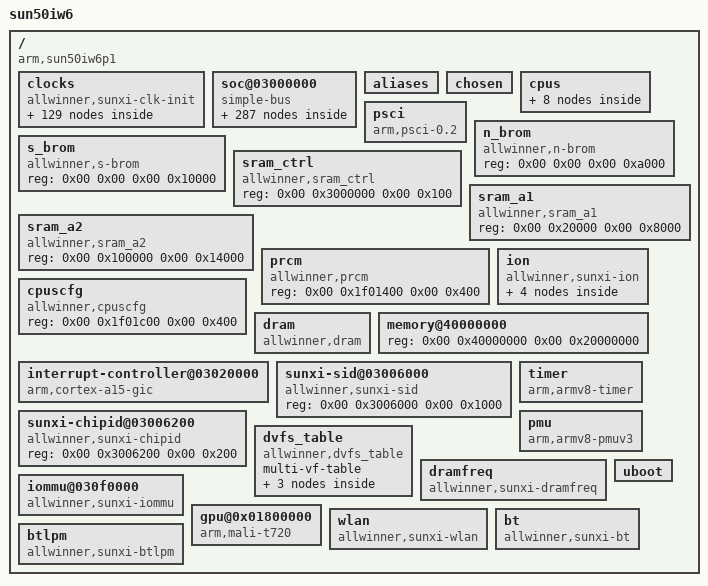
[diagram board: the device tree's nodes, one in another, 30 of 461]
/dts-v1/;

/memreserve/	0x0000000040020000 0x0000000000000800;
/memreserve/	0x0000000048000000 0x0000000001000000;
/memreserve/	0x0000000048100000 0x0000000000004000;
/memreserve/	0x0000000048104000 0x0000000000001000;
/memreserve/	0x0000000048105000 0x0000000000001000;
/ {
	model = "sun50iw6";
	compatible = "arm,sun50iw6p1";
	interrupt-parent = <0x01>;
	#address-cells = <0x02>;
	#size-cells = <0x02>;

	clocks {
		compatible = "allwinner,sunxi-clk-init";
		device_type = "clocks";
		#address-cells = <0x02>;
		#size-cells = <0x02>;
		ranges;
		reg = <0x00 0x3001000 0x00 0x1000 0x00 0x7010000 0x00 0x400 0x00 0x7000000 0x00 0x04>;

		losc {
			#clock-cells = <0x00>;
			compatible = "allwinner,fixed-clock";
			clock-frequency = <0x8000>;
			clock-output-names = "losc";
			linux,phandle = <0x0d>;
			phandle = <0x0d>;
		};

		iosc {
			#clock-cells = <0x00>;
			compatible = "allwinner,fixed-clock";
			clock-frequency = <0xf42400>;
			clock-output-names = "iosc";
			linux,phandle = <0x0e>;
			phandle = <0x0e>;
		};

		hosc {
			#clock-cells = <0x00>;
			compatible = "allwinner,fixed-clock";
			clock-frequency = <0x16e3600>;
			clock-output-names = "hosc";
			linux,phandle = <0x07>;
			phandle = <0x07>;
		};

		osc48m {
			#clock-cells = <0x00>;
			compatible = "allwinner,fixed-clock";
			clock-frequency = <0x2dc6c00>;
			clock-output-names = "osc48m";
			linux,phandle = <0x08>;
			phandle = <0x08>;
		};

		pll_cpu {
			#clock-cells = <0x00>;
			compatible = "allwinner,sunxi-pll-clock";
			lock-mode = "new";
			clock-output-names = "pll_cpu";
		};

		pll_ddr0 {
			#clock-cells = <0x00>;
			compatible = "allwinner,sunxi-pll-clock";
			lock-mode = "new";
			clock-output-names = "pll_ddr0";
			linux,phandle = <0xd7>;
			phandle = <0xd7>;
		};

		pll_periph0 {
			#clock-cells = <0x00>;
			compatible = "allwinner,sunxi-pll-clock";
			assigned-clock-rates = <0x23c34600>;
			lock-mode = "new";
			clock-output-names = "pll_periph0";
			linux,phandle = <0x02>;
			phandle = <0x02>;
		};

		pll_periph1 {
			#clock-cells = <0x00>;
			compatible = "allwinner,sunxi-pll-clock";
			assigned-clock-rates = <0x23c34600>;
			lock-mode = "new";
			clock-output-names = "pll_periph1";
			linux,phandle = <0x03>;
			phandle = <0x03>;
		};

		pll_gpu {
			#clock-cells = <0x00>;
			compatible = "allwinner,sunxi-pll-clock";
			lock-mode = "new";
			clock-output-names = "pll_gpu";
			linux,phandle = <0xd9>;
			phandle = <0xd9>;
		};

		pll_video0 {
			#clock-cells = <0x00>;
			compatible = "allwinner,sunxi-pll-clock";
			lock-mode = "new";
			clock-output-names = "pll_video0";
			linux,phandle = <0x05>;
			phandle = <0x05>;
		};

		pll_video1 {
			#clock-cells = <0x00>;
			compatible = "allwinner,sunxi-pll-clock";
			lock-mode = "new";
			assigned-clock-rates = <0x2367b880>;
			clock-output-names = "pll_video1";
			linux,phandle = <0x06>;
			phandle = <0x06>;
		};

		pll_ve {
			#clock-cells = <0x00>;
			compatible = "allwinner,sunxi-pll-clock";
			device_type = "clk_pll_ve";
			lock-mode = "new";
			clock-output-names = "pll_ve";
			linux,phandle = <0x17>;
			phandle = <0x17>;
		};

		pll_de {
			#clock-cells = <0x00>;
			compatible = "allwinner,sunxi-pll-clock";
			assigned-clock-rates = <0x297c1e00>;
			lock-mode = "new";
			clock-output-names = "pll_de";
			linux,phandle = <0x09>;
			phandle = <0x09>;
		};

		pll_hsic {
			#clock-cells = <0x00>;
			compatible = "allwinner,sunxi-pll-clock";
			lock-mode = "new";
			clock-output-names = "pll_hsic";
			linux,phandle = <0x3f>;
			phandle = <0x3f>;
		};

		pll_audio {
			#clock-cells = <0x00>;
			compatible = "allwinner,sunxi-pll-clock";
			lock-mode = "new";
			clock-output-names = "pll_audio";
			linux,phandle = <0x04>;
			phandle = <0x04>;
		};

		pll_periph0x2 {
			#clock-cells = <0x00>;
			compatible = "allwinner,fixed-factor-clock";
			clocks = <0x02>;
			clock-mult = <0x02>;
			clock-div = <0x01>;
			clock-output-names = "pll_periph0x2";
			linux,phandle = <0x1b>;
			phandle = <0x1b>;
		};

		pll_periph0x4 {
			#clock-cells = <0x00>;
			compatible = "allwinner,fixed-factor-clock";
			clocks = <0x02>;
			clock-mult = <0x04>;
			clock-div = <0x01>;
			clock-output-names = "pll_periph0x4";
		};

		periph32k {
			#clock-cells = <0x00>;
			compatible = "allwinner,fixed-factor-clock";
			clocks = <0x02>;
			clock-mult = <0x02>;
			clock-div = <0x8f0d>;
			clock-output-names = "periph32k";
		};

		pll_periph1x2 {
			#clock-cells = <0x00>;
			compatible = "allwinner,fixed-factor-clock";
			clocks = <0x03>;
			clock-mult = <0x02>;
			clock-div = <0x01>;
			clock-output-names = "pll_periph1x2";
			linux,phandle = <0x75>;
			phandle = <0x75>;
		};

		pll_audiox4 {
			#clock-cells = <0x00>;
			compatible = "allwinner,fixed-factor-clock";
			clocks = <0x04>;
			clock-mult = <0x04>;
			clock-div = <0x01>;
			clock-output-names = "pll_audiox4";
		};

		pll_audiox2 {
			#clock-cells = <0x00>;
			compatible = "allwinner,fixed-factor-clock";
			clocks = <0x04>;
			clock-mult = <0x02>;
			clock-div = <0x01>;
			clock-output-names = "pll_audiox2";
		};

		pll_video0x4 {
			#clock-cells = <0x00>;
			compatible = "allwinner,fixed-factor-clock";
			clocks = <0x05>;
			clock-mult = <0x04>;
			clock-div = <0x01>;
			clock-output-names = "pll_video0x4";
		};

		pll_video1x4 {
			#clock-cells = <0x00>;
			compatible = "allwinner,fixed-factor-clock";
			clocks = <0x06>;
			clock-mult = <0x04>;
			clock-div = <0x01>;
			clock-output-names = "pll_video1x4";
		};

		hoscd2 {
			#clock-cells = <0x00>;
			compatible = "allwinner,fixed-factor-clock";
			clocks = <0x07>;
			clock-mult = <0x01>;
			clock-div = <0x02>;
			clock-output-names = "hoscd2";
		};

		osc48md4 {
			#clock-cells = <0x00>;
			compatible = "allwinner,fixed-factor-clock";
			clocks = <0x08>;
			clock-mult = <0x01>;
			clock-div = <0x04>;
			clock-output-names = "osc48md4";
			linux,phandle = <0x39>;
			phandle = <0x39>;
		};

		pll_periph0d6 {
			#clock-cells = <0x00>;
			compatible = "allwinner,fixed-factor-clock";
			clocks = <0x02>;
			clock-mult = <0x01>;
			clock-div = <0x06>;
			clock-output-names = "pll_periph0d6";
		};

		cpu {
			#clock-cells = <0x00>;
			compatible = "allwinner,sunxi-periph-clock";
			clock-output-names = "cpu";
		};

		axi {
			#clock-cells = <0x00>;
			compatible = "allwinner,sunxi-periph-clock";
			clock-output-names = "axi";
		};

		cpuapb {
			#clock-cells = <0x00>;
			compatible = "allwinner,sunxi-periph-clock";
			clock-output-names = "cpuapb";
		};

		psi {
			#clock-cells = <0x00>;
			compatible = "allwinner,sunxi-periph-clock";
			clock-output-names = "psi";
		};

		ahb1 {
			#clock-cells = <0x00>;
			compatible = "allwinner,sunxi-periph-clock";
			clock-output-names = "ahb1";
		};

		ahb2 {
			#clock-cells = <0x00>;
			compatible = "allwinner,sunxi-periph-clock";
			clock-output-names = "ahb2";
		};

		ahb3 {
			#clock-cells = <0x00>;
			compatible = "allwinner,sunxi-periph-clock";
			clock-output-names = "ahb3";
		};

		apb1 {
			#clock-cells = <0x00>;
			compatible = "allwinner,sunxi-periph-clock";
			clock-output-names = "apb1";
		};

		apb2 {
			#clock-cells = <0x00>;
			compatible = "allwinner,sunxi-periph-clock";
			clock-output-names = "apb2";
			linux,phandle = <0xae>;
			phandle = <0xae>;
		};

		mbus {
			#clock-cells = <0x00>;
			compatible = "allwinner,sunxi-periph-clock";
			clock-output-names = "mbus";
		};

		de {
			#clock-cells = <0x00>;
			compatible = "allwinner,sunxi-periph-clock";
			assigned-clock-parents = <0x09>;
			assigned-clock-rates = <0x297c1e00>;
			clock-output-names = "de";
			linux,phandle = <0x87>;
			phandle = <0x87>;
		};

		di {
			#clock-cells = <0x00>;
			compatible = "allwinner,sunxi-periph-clock";
			clock-output-names = "di";
			linux,phandle = <0xac>;
			phandle = <0xac>;
		};

		gpu {
			#clock-cells = <0x00>;
			compatible = "allwinner,sunxi-periph-clock";
			clock-output-names = "gpu";
			linux,phandle = <0xda>;
			phandle = <0xda>;
		};

		ce {
			#clock-cells = <0x00>;
			compatible = "allwinner,sunxi-periph-clock";
			clock-output-names = "ce";
			linux,phandle = <0xab>;
			phandle = <0xab>;
		};

		ve {
			#clock-cells = <0x00>;
			compatible = "allwinner,sunxi-periph-clock";
			clock-output-names = "ve";
			linux,phandle = <0x18>;
			phandle = <0x18>;
		};

		emce {
			#clock-cells = <0x00>;
			compatible = "allwinner,sunxi-periph-clock";
			clock-output-names = "emce";
			linux,phandle = <0xaa>;
			phandle = <0xaa>;
		};

		vp9 {
			#clock-cells = <0x00>;
			compatible = "allwinner,sunxi-periph-clock";
			clock-output-names = "vp9";
			linux,phandle = <0x1a>;
			phandle = <0x1a>;
		};

		dma {
			#clock-cells = <0x00>;
			compatible = "allwinner,sunxi-periph-clock";
			clock-output-names = "dma";
			linux,phandle = <0x0c>;
			phandle = <0x0c>;
		};

		msgbox {
			#clock-cells = <0x00>;
			compatible = "allwinner,sunxi-periph-clock";
			clock-output-names = "msgbox";
			linux,phandle = <0x0f>;
			phandle = <0x0f>;
		};

		hwspinlock_rst {
			#clock-cells = <0x00>;
			compatible = "allwinner,sunxi-periph-clock";
			clock-output-names = "hwspinlock_rst";
			linux,phandle = <0x10>;
			phandle = <0x10>;
		};

		hwspinlock_bus {
			#clock-cells = <0x00>;
			compatible = "allwinner,sunxi-periph-clock";
			clock-output-names = "hwspinlock_bus";
			linux,phandle = <0x11>;
			phandle = <0x11>;
		};

		hstimer {
			#clock-cells = <0x00>;
			compatible = "allwinner,sunxi-periph-clock";
			clock-output-names = "hstimer";
		};

		avs {
			#clock-cells = <0x00>;
			compatible = "allwinner,sunxi-periph-clock";
			clock-output-names = "avs";
		};

		dbgsys {
			#clock-cells = <0x00>;
			compatible = "allwinner,sunxi-periph-clock";
			clock-output-names = "dbgsys";
		};

		pwm {
			#clock-cells = <0x00>;
			compatible = "allwinner,sunxi-periph-clock";
			clock-output-names = "pwm";
			linux,phandle = <0x93>;
			phandle = <0x93>;
		};

		iommu {
			#clock-cells = <0x00>;
			compatible = "allwinner,sunxi-periph-clock";
			clock-output-names = "iommu";
			linux,phandle = <0xd8>;
			phandle = <0xd8>;
		};

		sdram {
			#clock-cells = <0x00>;
			compatible = "allwinner,sunxi-periph-clock";
			clock-output-names = "sdram";
		};

		nand0 {
			#clock-cells = <0x00>;
			compatible = "allwinner,sunxi-periph-clock";
			clock-output-names = "nand0";
			linux,phandle = <0xb6>;
			phandle = <0xb6>;
		};

		nand1 {
			#clock-cells = <0x00>;
			compatible = "allwinner,sunxi-periph-clock";
			clock-output-names = "nand1";
			linux,phandle = <0xb7>;
			phandle = <0xb7>;
		};

		sdmmc0_mod {
			#clock-cells = <0x00>;
			compatible = "allwinner,sunxi-periph-clock";
			clock-output-names = "sdmmc0_mod";
			linux,phandle = <0x7b>;
			phandle = <0x7b>;
		};

		sdmmc0_bus {
			#clock-cells = <0x00>;
			compatible = "allwinner,sunxi-periph-clock";
			clock-output-names = "sdmmc0_bus";
			linux,phandle = <0x7c>;
			phandle = <0x7c>;
		};

		sdmmc0_rst {
			#clock-cells = <0x00>;
			compatible = "allwinner,sunxi-periph-clock";
			clock-output-names = "sdmmc0_rst";
			linux,phandle = <0x7d>;
			phandle = <0x7d>;
		};

		sdmmc1_mod {
			#clock-cells = <0x00>;
			compatible = "allwinner,sunxi-periph-clock";
			clock-output-names = "sdmmc1_mod";
			linux,phandle = <0x82>;
			phandle = <0x82>;
		};

		sdmmc1_bus {
			#clock-cells = <0x00>;
			compatible = "allwinner,sunxi-periph-clock";
			clock-output-names = "sdmmc1_bus";
			linux,phandle = <0x83>;
			phandle = <0x83>;
		};

		sdmmc1_rst {
			#clock-cells = <0x00>;
			compatible = "allwinner,sunxi-periph-clock";
			clock-output-names = "sdmmc1_rst";
			linux,phandle = <0x84>;
			phandle = <0x84>;
		};

		sdmmc2_mod {
			#clock-cells = <0x00>;
			compatible = "allwinner,sunxi-periph-clock";
			clock-output-names = "sdmmc2_mod";
			linux,phandle = <0x76>;
			phandle = <0x76>;
		};

		sdmmc2_bus {
			#clock-cells = <0x00>;
			compatible = "allwinner,sunxi-periph-clock";
			clock-output-names = "sdmmc2_bus";
			linux,phandle = <0x77>;
			phandle = <0x77>;
		};

		sdmmc2_rst {
			#clock-cells = <0x00>;
			compatible = "allwinner,sunxi-periph-clock";
			clock-output-names = "sdmmc2_rst";
			linux,phandle = <0x78>;
			phandle = <0x78>;
		};

		uart0 {
			#clock-cells = <0x00>;
			compatible = "allwinner,sunxi-periph-clock";
			clock-output-names = "uart0";
			linux,phandle = <0x1c>;
			phandle = <0x1c>;
		};

		uart1 {
			#clock-cells = <0x00>;
			compatible = "allwinner,sunxi-periph-clock";
			clock-output-names = "uart1";
			linux,phandle = <0x1f>;
			phandle = <0x1f>;
		};

		uart2 {
			#clock-cells = <0x00>;
			compatible = "allwinner,sunxi-periph-clock";
			clock-output-names = "uart2";
			linux,phandle = <0x22>;
			phandle = <0x22>;
		};

		uart3 {
			#clock-cells = <0x00>;
			compatible = "allwinner,sunxi-periph-clock";
			clock-output-names = "uart3";
			linux,phandle = <0x25>;
			phandle = <0x25>;
		};

		twi0 {
			#clock-cells = <0x00>;
			compatible = "allwinner,sunxi-periph-clock";
			clock-output-names = "twi0";
			linux,phandle = <0x28>;
			phandle = <0x28>;
		};

		twi1 {
			#clock-cells = <0x00>;
			compatible = "allwinner,sunxi-periph-clock";
			clock-output-names = "twi1";
			linux,phandle = <0x2b>;
			phandle = <0x2b>;
		};

		twi2 {
			#clock-cells = <0x00>;
			compatible = "allwinner,sunxi-periph-clock";
			clock-output-names = "twi2";
			linux,phandle = <0x2e>;
			phandle = <0x2e>;
		};

		twi3 {
			#clock-cells = <0x00>;
			compatible = "allwinner,sunxi-periph-clock";
			clock-output-names = "twi3";
			linux,phandle = <0x31>;
			phandle = <0x31>;
		};

		scr0 {
			#clock-cells = <0x00>;
			compatible = "allwinner,sunxi-periph-clock";
			clock-output-names = "scr0";
			linux,phandle = <0xad>;
			phandle = <0xad>;
		};

		scr1 {
			#clock-cells = <0x00>;
			compatible = "allwinner,sunxi-periph-clock";
			clock-output-names = "scr1";
			linux,phandle = <0xb2>;
			phandle = <0xb2>;
		};

		spi0 {
			#clock-cells = <0x00>;
			compatible = "allwinner,sunxi-periph-clock";
			clock-output-names = "spi0";
			linux,phandle = <0x67>;
			phandle = <0x67>;
		};

		spi1 {
			#clock-cells = <0x00>;
			compatible = "allwinner,sunxi-periph-clock";
			clock-output-names = "spi1";
			linux,phandle = <0x6b>;
			phandle = <0x6b>;
		};

		gmac {
			#clock-cells = <0x00>;
			compatible = "allwinner,sunxi-periph-clock";
			clock-output-names = "gmac";
			linux,phandle = <0xd2>;
			phandle = <0xd2>;
		};

		sata {
			#clock-cells = <0x00>;
			compatible = "allwinner,sunxi-periph-clock";
			clock-output-names = "sata";
		};

		sata_24m {
			#clock-cells = <0x00>;
			compatible = "allwinner,sunxi-periph-clock";
			clock-output-names = "sata_24m";
		};

		ts {
			#clock-cells = <0x00>;
			compatible = "allwinner,sunxi-periph-clock";
			clock-output-names = "ts";
			linux,phandle = <0xbb>;
			phandle = <0xbb>;
		};

		irtx {
			#clock-cells = <0x00>;
			compatible = "allwinner,sunxi-periph-clock";
			clock-output-names = "irtx";
		};

		ths {
			#clock-cells = <0x00>;
			compatible = "allwinner,sunxi-periph-clock";
			clock-output-names = "ths";
			linux,phandle = <0xc4>;
			phandle = <0xc4>;
		};

		i2s0 {
			#clock-cells = <0x00>;
			compatible = "allwinner,sunxi-periph-clock";
			clock-output-names = "i2s0";
			linux,phandle = <0x42>;
			phandle = <0x42>;
		};

		i2s1 {
			#clock-cells = <0x00>;
			compatible = "allwinner,sunxi-periph-clock";
			clock-output-names = "i2s1";
			linux,phandle = <0x45>;
			phandle = <0x45>;
		};

		i2s2 {
			#clock-cells = <0x00>;
			compatible = "allwinner,sunxi-periph-clock";
			clock-output-names = "i2s2";
			linux,phandle = <0x46>;
			phandle = <0x46>;
		};

		i2s3 {
			#clock-cells = <0x00>;
			compatible = "allwinner,sunxi-periph-clock";
			clock-output-names = "i2s3";
			linux,phandle = <0x49>;
			phandle = <0x49>;
		};

		spdif {
			#clock-cells = <0x00>;
			compatible = "allwinner,sunxi-periph-clock";
			clock-output-names = "spdif";
			linux,phandle = <0x4c>;
			phandle = <0x4c>;
		};

		dmic {
			#clock-cells = <0x00>;
			compatible = "allwinner,sunxi-periph-clock";
			clock-output-names = "dmic";
			linux,phandle = <0x4f>;
			phandle = <0x4f>;
		};

		ahub {
			#clock-cells = <0x00>;
			compatible = "allwinner,sunxi-periph-clock";
			clock-output-names = "ahub";
			linux,phandle = <0x52>;
			phandle = <0x52>;
		};

		usbphy0 {
			#clock-cells = <0x00>;
			compatible = "allwinner,sunxi-periph-clock";
			clock-output-names = "usbphy0";
			linux,phandle = <0x34>;
			phandle = <0x34>;
		};

		usbphy1 {
			#clock-cells = <0x00>;
			compatible = "allwinner,sunxi-periph-clock";
			clock-output-names = "usbphy1";
			linux,phandle = <0x3a>;
			phandle = <0x3a>;
		};

		usbphy3 {
			#clock-cells = <0x00>;
			compatible = "allwinner,sunxi-periph-clock";
			clock-output-names = "usbphy3";
			linux,phandle = <0x3c>;
			phandle = <0x3c>;
		};

		usbohci0 {
			#clock-cells = <0x00>;
			compatible = "allwinner,sunxi-periph-clock";
			clock-output-names = "usbohci0";
			linux,phandle = <0x37>;
			phandle = <0x37>;
		};

		usbohci0_12m {
			#clock-cells = <0x00>;
			compatible = "allwinner,sunxi-periph-clock";
			clock-output-names = "usbohci0_12m";
			linux,phandle = <0x38>;
			phandle = <0x38>;
		};

		usbohci3 {
			#clock-cells = <0x00>;
			compatible = "allwinner,sunxi-periph-clock";
			clock-output-names = "usbohci3";
			linux,phandle = <0x40>;
			phandle = <0x40>;
		};

		usbohci3_12m {
			#clock-cells = <0x00>;
			compatible = "allwinner,sunxi-periph-clock";
			clock-output-names = "usbohci3_12m";
			linux,phandle = <0x41>;
			phandle = <0x41>;
		};

		usbehci0 {
			#clock-cells = <0x00>;
			compatible = "allwinner,sunxi-periph-clock";
			clock-output-names = "usbehci0";
			linux,phandle = <0x36>;
			phandle = <0x36>;
		};

		usbehci3 {
			#clock-cells = <0x00>;
			compatible = "allwinner,sunxi-periph-clock";
			clock-output-names = "usbehci3";
			linux,phandle = <0x3d>;
			phandle = <0x3d>;
		};

		usb3_0_host {
			#clock-cells = <0x00>;
			compatible = "allwinner,sunxi-periph-clock";
			clock-output-names = "usb3_0_host";
			linux,phandle = <0x3b>;
			phandle = <0x3b>;
		};

		usbotg {
			#clock-cells = <0x00>;
			compatible = "allwinner,sunxi-periph-clock";
			clock-output-names = "usbotg";
			linux,phandle = <0x35>;
			phandle = <0x35>;
		};

		usbhsic {
			#clock-cells = <0x00>;
			compatible = "allwinner,sunxi-periph-clock";
			clock-output-names = "usbhsic";
			linux,phandle = <0x3e>;
			phandle = <0x3e>;
		};

		pcieref {
			#clock-cells = <0x00>;
			compatible = "allwinner,sunxi-periph-clock";
			clock-output-names = "pcieref";
			linux,phandle = <0x6f>;
			phandle = <0x6f>;
		};

		pciemaxi {
			#clock-cells = <0x00>;
			compatible = "allwinner,sunxi-periph-clock";
			assigned-clock-rates = <0xbebc200>;
			clock-output-names = "pciemaxi";
			linux,phandle = <0x70>;
			phandle = <0x70>;
		};

		pcieaux {
			#clock-cells = <0x00>;
			compatible = "allwinner,sunxi-periph-clock";
			assigned-clock-rates = <0xf4240>;
			clock-output-names = "pcieaux";
			linux,phandle = <0x71>;
			phandle = <0x71>;
		};

		pcie_bus {
			#clock-cells = <0x00>;
			compatible = "allwinner,sunxi-periph-clock";
			clock-output-names = "pcie_bus";
			linux,phandle = <0x72>;
			phandle = <0x72>;
		};

		pcie_power {
			#clock-cells = <0x00>;
			compatible = "allwinner,sunxi-periph-clock";
			clock-output-names = "pcie_power";
			linux,phandle = <0x73>;
			phandle = <0x73>;
		};

		pcie_rst {
			#clock-cells = <0x00>;
			compatible = "allwinner,sunxi-periph-clock";
			clock-output-names = "pcie_rst";
			linux,phandle = <0x74>;
			phandle = <0x74>;
		};

		hdmi {
			#clock-cells = <0x00>;
			compatible = "allwinner,sunxi-periph-clock";
			assigned-clock-parents = <0x06>;
			clock-output-names = "hdmi";
			linux,phandle = <0x8b>;
			phandle = <0x8b>;
		};

		hdmi_slow {
			#clock-cells = <0x00>;
			compatible = "allwinner,sunxi-periph-clock";
			clock-output-names = "hdmi_slow";
			linux,phandle = <0x8c>;
			phandle = <0x8c>;
		};

		hdmi_cec {
			#clock-cells = <0x00>;
			compatible = "allwinner,sunxi-periph-clock";
			clock-output-names = "hdmi_cec";
			linux,phandle = <0x8e>;
			phandle = <0x8e>;
		};

		display_top {
			#clock-cells = <0x00>;
			compatible = "allwinner,sunxi-periph-clock";
			clock-output-names = "display_top";
			linux,phandle = <0x88>;
			phandle = <0x88>;
		};

		tcon_lcd {
			#clock-cells = <0x00>;
			compatible = "allwinner,sunxi-periph-clock";
			clock-output-names = "tcon_lcd";
			linux,phandle = <0x89>;
			phandle = <0x89>;
		};

		tcon_tv {
			#clock-cells = <0x00>;
			compatible = "allwinner,sunxi-periph-clock";
			assigned-clock-parents = <0x06>;
			clock-output-names = "tcon_tv";
			linux,phandle = <0x8a>;
			phandle = <0x8a>;
		};

		csi_misc {
			#clock-cells = <0x00>;
			compatible = "allwinner,sunxi-periph-clock";
			clock-output-names = "csi_misc";
			linux,phandle = <0x9e>;
			phandle = <0x9e>;
		};

		csi_top {
			#clock-cells = <0x00>;
			compatible = "allwinner,sunxi-periph-clock";
			clock-output-names = "csi_top";
			linux,phandle = <0x9a>;
			phandle = <0x9a>;
		};

		csi_master0 {
			#clock-cells = <0x00>;
			compatible = "allwinner,sunxi-periph-clock";
			clock-output-names = "csi_master0";
			linux,phandle = <0x9b>;
			phandle = <0x9b>;
		};

		hdmi_hdcp {
			#clock-cells = <0x00>;
			compatible = "allwinner,sunxi-periph-clock";
			assigned-clock-parents = <0x03>;
			clock-output-names = "hdmi_hdcp";
			linux,phandle = <0x8d>;
			phandle = <0x8d>;
		};

		pio {
			#clock-cells = <0x00>;
			compatible = "allwinner,sunxi-periph-clock";
			clock-output-names = "pio";
			linux,phandle = <0x0b>;
			phandle = <0x0b>;
		};

		cpurcir {
			#clock-cells = <0x00>;
			compatible = "allwinner,sunxi-periph-cpus-clock";
			clock-output-names = "cpurcir";
			linux,phandle = <0x13>;
			phandle = <0x13>;
		};

		losc_out {
			#clock-cells = <0x00>;
			compatible = "allwinner,sunxi-periph-cpus-clock";
			clock-output-names = "losc_out";
			linux,phandle = <0xdb>;
			phandle = <0xdb>;
		};

		cpurcpus_pll {
			#clock-cells = <0x00>;
			compatible = "allwinner,sunxi-periph-cpus-clock";
			clock-output-names = "cpurcpus_pll";
		};

		cpurcpus {
			#clock-cells = <0x00>;
			compatible = "allwinner,sunxi-periph-cpus-clock";
			clock-output-names = "cpurcpus";
		};

		cpurahbs {
			#clock-cells = <0x00>;
			compatible = "allwinner,sunxi-periph-cpus-clock";
			clock-output-names = "cpurahbs";
		};

		cpurapbs1 {
			#clock-cells = <0x00>;
			compatible = "allwinner,sunxi-periph-cpus-clock";
			clock-output-names = "cpurapbs1";
		};

		cpurapbs2_pll {
			#clock-cells = <0x00>;
			compatible = "allwinner,sunxi-periph-cpus-clock";
			clock-output-names = "cpurapbs2_pll";
		};

		cpurapbs2 {
			#clock-cells = <0x00>;
			compatible = "allwinner,sunxi-periph-cpus-clock";
			clock-output-names = "cpurapbs2";
		};

		cpurpio {
			#clock-cells = <0x00>;
			compatible = "allwinner,sunxi-periph-cpus-clock";
			clock-output-names = "cpurpio";
			linux,phandle = <0x0a>;
			phandle = <0x0a>;
		};

		spwm {
			#clock-cells = <0x00>;
			compatible = "allwinner,sunxi-periph-cpus-clock";
			clock-output-names = "spwm";
			linux,phandle = <0x96>;
			phandle = <0x96>;
		};

		dcxo_out {
			#clock-cells = <0x00>;
			compatible = "allwinner,sunxi-periph-cpus-clock";
			clock-output-names = "dcxo_out";
		};
	};

	soc@03000000 {
		compatible = "simple-bus";
		#address-cells = <0x02>;
		#size-cells = <0x02>;
		ranges;
		device_type = "soc";

		pinctrl@07022000 {
			compatible = "allwinner,sun50iw6p1-r-pinctrl";
			reg = <0x00 0x7022000 0x00 0x400>;
			interrupts = <0x00 0x69 0x04 0x00 0x6f 0x04>;
			clocks = <0x0a>;
			device_type = "r_pio";
			gpio-controller;
			interrupt-controller;
			#interrupt-cells = <0x02>;
			#size-cells = <0x00>;
			#gpio-cells = <0x06>;
			linux,phandle = <0xdc>;
			phandle = <0xdc>;

			s_cir0@0 {
				allwinner,pins = "PL9";
				allwinner,function = "s_cir0";
				allwinner,muxsel = <0x02>;
				allwinner,drive = <0x02>;
				allwinner,pull = <0x01>;
				linux,phandle = <0x12>;
				phandle = <0x12>;
			};

			pwm16@0 {
				linux,phandle = <0x105>;
				phandle = <0x105>;
				allwinner,pins = "PL8";
				allwinner,function = "pwm16";
				allwinner,pname = "pwm_positive";
				allwinner,muxsel = <0x02>;
				allwinner,pull = <0x00>;
				allwinner,drive = <0xffffffff>;
				allwinner,data = <0xffffffff>;
			};

			pwm16@1 {
				linux,phandle = <0x106>;
				phandle = <0x106>;
				allwinner,pins = "PL8";
				allwinner,function = "pwm16";
				allwinner,pname = "pwm_positive";
				allwinner,muxsel = <0x07>;
				allwinner,pull = <0x00>;
				allwinner,drive = <0xffffffff>;
				allwinner,data = <0xffffffff>;
			};

			s_uart0@0 {
				linux,phandle = <0x10c>;
				phandle = <0x10c>;
				allwinner,pins = "PL2\0PL3";
				allwinner,function = "s_uart0";
				allwinner,pname = "s_uart0_tx\0s_uart0_rx";
				allwinner,muxsel = <0x02>;
				allwinner,pull = <0xffffffff>;
				allwinner,drive = <0xffffffff>;
				allwinner,data = <0xffffffff>;
			};

			s_twi0@0 {
				linux,phandle = <0x10d>;
				phandle = <0x10d>;
				allwinner,pins = "PL0\0PL1";
				allwinner,function = "s_twi0";
				allwinner,pname = "s_twi0_sck\0s_twi0_sda";
				allwinner,muxsel = <0x02>;
				allwinner,pull = <0x01>;
				allwinner,drive = <0x02>;
				allwinner,data = <0xffffffff>;
			};

			s_jtag0@0 {
				linux,phandle = <0x10e>;
				phandle = <0x10e>;
				allwinner,pins = "PL4\0PL5\0PL6\0PL7";
				allwinner,function = "s_jtag0";
				allwinner,pname = "s_jtag0_tms\0s_jtag0_tck\0s_jtag0_tdo\0s_jtag0_tdi";
				allwinner,muxsel = <0x02>;
				allwinner,pull = <0x01>;
				allwinner,drive = <0x02>;
				allwinner,data = <0xffffffff>;
			};
		};

		pinctrl@0300b000 {
			compatible = "allwinner,sun50iw6p1-pinctrl";
			reg = <0x00 0x300b000 0x00 0x400>;
			interrupts = <0x00 0x33 0x04 0x00 0x35 0x04 0x00 0x36 0x04 0x00 0x3b 0x04>;
			device_type = "pio";
			clocks = <0x0b>;
			gpio-controller;
			interrupt-controller;
			#interrupt-cells = <0x02>;
			#size-cells = <0x00>;
			#gpio-cells = <0x06>;
			linux,phandle = <0x81>;
			phandle = <0x81>;

			twi3@1 {
				allwinner,pins = "PB17\0PB18";
				allwinner,function = "io_disabled";
				allwinner,muxsel = <0x07>;
				allwinner,drive = <0x01>;
				allwinner,pull = <0x00>;
				linux,phandle = <0x33>;
				phandle = <0x33>;
			};

			ts0@0 {
				allwinner,pins = "PD0\0PD1\0PD2\0PD3\0PD4\0PD5\0PD6\0PD7\0PD8\0PD9\0PD10\0PD11";
				allwinner,pname = "ts0_clk\0ts0_err\0ts0_sync\0ts0_dvld\0ts0_d0\0ts0_d1\0ts0_d2\0ts0_d3\0ts0_d4\0ts0_d5\0ts0_d6\0ts0_d7";
				allwinner,function = "ts0";
				allwinner,muxsel = <0x03>;
				allwinner,drive = <0x01>;
				allwinner,pull = <0x00>;
				linux,phandle = <0xbc>;
				phandle = <0xbc>;
			};

			ts0_sleep@0 {
				allwinner,pins = "PD0\0PD1\0PD2\0PD3\0PD4\0PD5\0PD6\0PD7\0PD8\0PD9\0PD10\0PD11";
				allwinner,pname = "ts0_clk\0ts0_err\0ts0_sync\0ts0_dvld\0ts0_d0\0ts0_d1\0ts0_d2\0ts0_d3\0ts0_d4\0ts0_d5\0ts0_d6\0ts0_d7";
				allwinner,function = "io_disabled";
				allwinner,muxsel = <0x07>;
				allwinner,drive = <0x01>;
				allwinner,pull = <0x00>;
				linux,phandle = <0xc0>;
				phandle = <0xc0>;
			};

			ts1@0 {
				allwinner,pins = "PD12\0PD13\0PD14\0PD15\0PD16";
				allwinner,pname = "ts1_clk\0ts1_err\0ts1_sync\0ts1_dvld\0ts1_d0";
				allwinner,function = "ts1";
				allwinner,muxsel = <0x03>;
				allwinner,drive = <0x01>;
				allwinner,pull = <0x00>;
				linux,phandle = <0xbd>;
				phandle = <0xbd>;
			};

			ts1_sleep@0 {
				allwinner,pins = "PD12\0PD13\0PD14\0PD15\0PD16";
				allwinner,pname = "ts1_clk\0ts1_err\0ts1_sync\0ts1_dvld\0ts1_d0";
				allwinner,function = "io_disabled";
				allwinner,muxsel = <0x07>;
				allwinner,drive = <0x01>;
				allwinner,pull = <0x00>;
				linux,phandle = <0xc1>;
				phandle = <0xc1>;
			};

			ts2@0 {
				allwinner,pins = "PD17\0PD18\0PD19\0PD20\0PD21";
				allwinner,pname = "ts2_clk\0ts2_err\0ts2_sync\0ts2_dvld\0ts2_d0";
				allwinner,function = "ts2";
				allwinner,muxsel = <0x03>;
				allwinner,drive = <0x01>;
				allwinner,pull = <0x00>;
				linux,phandle = <0xbe>;
				phandle = <0xbe>;
			};

			ts2_sleep@0 {
				allwinner,pins = "PD17\0PD18\0PD19\0PD20\0PD21";
				allwinner,pname = "ts2_clk\0ts2_err\0ts2_sync\0ts2_dvld\0ts2_d0";
				allwinner,function = "io_disabled";
				allwinner,muxsel = <0x07>;
				allwinner,drive = <0x01>;
				allwinner,pull = <0x00>;
				linux,phandle = <0xc2>;
				phandle = <0xc2>;
			};

			ts3@0 {
				allwinner,pins = "PD22\0PD23\0PD24\0PD25\0PD26";
				allwinner,pname = "ts3_clk\0ts3_err\0ts3_sync\0ts3_dvld\0ts3_d0";
				allwinner,function = "ts3";
				allwinner,muxsel = <0x03>;
				allwinner,drive = <0x01>;
				allwinner,pull = <0x00>;
				linux,phandle = <0xbf>;
				phandle = <0xbf>;
			};

			ts3_sleep@0 {
				allwinner,pins = "PD22\0PD23\0PD24\0PD25\0PD26";
				allwinner,pname = "ts3_clk\0ts3_err\0ts3_sync\0ts3_dvld\0ts3_d0";
				allwinner,function = "io_disabled";
				allwinner,muxsel = <0x07>;
				allwinner,drive = <0x01>;
				allwinner,pull = <0x00>;
				linux,phandle = <0xc3>;
				phandle = <0xc3>;
			};

			sdc0@1 {
				allwinner,pins = "PF0\0PF1\0PF2\0PF3\0PF4\0PF5";
				allwinner,function = "io_disabled";
				allwinner,muxsel = <0x07>;
				allwinner,drive = <0x01>;
				allwinner,pull = <0x01>;
				linux,phandle = <0x7f>;
				phandle = <0x7f>;
			};

			sdc0@2 {
				allwinner,pins = "PF2\0PF4";
				allwinner,function = "uart0";
				allwinner,muxsel = <0x03>;
				allwinner,drive = <0x01>;
				allwinner,pull = <0x01>;
				linux,phandle = <0x80>;
				phandle = <0x80>;
			};

			sdc1@1 {
				allwinner,pins = "PG0\0PG1\0PG2\0PG3\0PG4\0PG5";
				allwinner,function = "io_disabled";
				allwinner,muxsel = <0x07>;
				allwinner,drive = <0x01>;
				allwinner,pull = <0x01>;
				linux,phandle = <0x86>;
				phandle = <0x86>;
			};

			sdc2@1 {
				allwinner,pins = "PC1\0PC4\0PC5\0PC6\0PC7\0PC8\0PC9\0PC10\0PC11\0PC12\0PC13\0PC14";
				allwinner,function = "io_disabled";
				allwinner,muxsel = <0x07>;
				allwinner,drive = <0x01>;
				allwinner,pull = <0x01>;
				linux,phandle = <0x7a>;
				phandle = <0x7a>;
			};

			daudio0@0 {
				allwinner,pins = "PH0\0PH1\0PH2\0PH3\0PH4";
				allwinner,function = "pcm0";
				allwinner,muxsel = <0x03>;
				allwinner,drive = <0x01>;
				allwinner,pull = <0x00>;
				linux,phandle = <0x43>;
				phandle = <0x43>;
			};

			daudio0_sleep@0 {
				allwinner,pins = "PH0\0PH1\0PH2\0PH3\0PH4";
				allwinner,function = "io_disabled";
				allwinner,muxsel = <0x07>;
				allwinner,drive = <0x01>;
				allwinner,pull = <0x00>;
				linux,phandle = <0x44>;
				phandle = <0x44>;
			};

			daudio2@0 {
				allwinner,pins = "PG10\0PG11\0PG12\0PG13\0PG14";
				allwinner,function = "pcm2";
				allwinner,muxsel = <0x02>;
				allwinner,drive = <0x01>;
				allwinner,pull = <0x00>;
				linux,phandle = <0x47>;
				phandle = <0x47>;
			};

			daudio2_sleep@0 {
				allwinner,pins = "PG10\0PG11\0PG12\0PG13\0PG14";
				allwinner,function = "io_disabled";
				allwinner,muxsel = <0x07>;
				allwinner,drive = <0x01>;
				allwinner,pull = <0x00>;
				linux,phandle = <0x48>;
				phandle = <0x48>;
			};

			daudio3@0 {
				allwinner,pins = "PB12\0PB13\0PB14\0PB15\0PB16";
				allwinner,function = "pcm3";
				allwinner,muxsel = <0x02>;
				allwinner,driver = <0x01>;
				allwinner,pull = <0x00>;
				linux,phandle = <0x4a>;
				phandle = <0x4a>;
			};

			daudio3_sleep@0 {
				allwinner,pins = "PB12\0PB13\0PB14\0PB15\0PB16";
				allwinner,function = "io_disabled";
				allwinner,muxsel = <0x07>;
				allwinner,driver = <0x01>;
				allwinner,pull = <0x00>;
				linux,phandle = <0x4b>;
				phandle = <0x4b>;
			};

			spdif@0 {
				allwinner,pins = "PH5\0PH6\0PH7";
				allwinner,function = "spdif0";
				allwinner,muxsel = <0x03>;
				allwinner,drive = <0x01>;
				allwinner,pull = <0x00>;
				linux,phandle = <0x4d>;
				phandle = <0x4d>;
			};

			spdif_sleep@0 {
				allwinner,pins = "PH5\0PH6\0PH7";
				allwinner,function = "io_disabled";
				allwinner,muxsel = <0x07>;
				allwinner,drive = <0x01>;
				allwinner,pull = <0x00>;
				linux,phandle = <0x4e>;
				phandle = <0x4e>;
			};

			dmic@0 {
				allwinner,pins = "PD14\0PD15\0PD16\0PD17\0PD18";
				allwinner,function = "dmic";
				allwinner,muxsel = <0x04>;
				allwinner,driver = <0x01>;
				allwinner,pull = <0x00>;
				linux,phandle = <0x50>;
				phandle = <0x50>;
			};

			dmic_sleep@0 {
				allwinner,pins = "PD14\0PD15\0PD16\0PD17\0PD18";
				allwinner,function = "io_disabled";
				allwinner,muxsel = <0x07>;
				allwinner,driver = <0x01>;
				allwinner,pull = <0x00>;
				linux,phandle = <0x51>;
				phandle = <0x51>;
			};

			ahub_daudio0@0 {
				allwinner,pins = "PH0\0PH1\0PH2\0PH3\0PH4";
				allwinner,function = "pcm0";
				allwinner,muxsel = <0x04>;
				allwinner,driver = <0x01>;
				allwinner,pull = <0x00>;
				linux,phandle = <0x53>;
				phandle = <0x53>;
			};

			ahub_daudio0_sleep@0 {
				allwinner,pins = "PH0\0PH1\0PH2\0PH3\0PH4";
				allwinner,function = "io_disabled";
				allwinner,muxsel = <0x07>;
				allwinner,driver = <0x01>;
				allwinner,pull = <0x00>;
				linux,phandle = <0x54>;
				phandle = <0x54>;
			};

			ahub_daudio2@0 {
				allwinner,pins = "PG10\0PG11\0PG12\0PG13\0PG14";
				allwinner,function = "pcm2";
				allwinner,muxsel = <0x03>;
				allwinner,drive = <0x01>;
				allwinner,pull = <0x00>;
				linux,phandle = <0x55>;
				phandle = <0x55>;
			};

			ahub_daudio2_sleep@0 {
				allwinner,pins = "PG10\0PG11\0PG12\0PG13\0PG14";
				allwinner,function = "io_disabled";
				allwinner,muxsel = <0x07>;
				allwinner,drive = <0x01>;
				allwinner,pull = <0x00>;
				linux,phandle = <0x56>;
				phandle = <0x56>;
			};

			ahub_daudio3@0 {
				allwinner,pins = "PB12\0PB13\0PB14\0PB15\0PB16";
				allwinner,function = "pcm3";
				allwinner,muxsel = <0x04>;
				allwinner,driver = <0x01>;
				allwinner,pull = <0x00>;
				linux,phandle = <0x57>;
				phandle = <0x57>;
			};

			ahub_daudio3_sleep@0 {
				allwinner,pins = "PB12\0PB13\0PB14\0PB15\0PB16";
				allwinner,function = "io_disabled";
				allwinner,muxsel = <0x07>;
				allwinner,driver = <0x01>;
				allwinner,pull = <0x00>;
				linux,phandle = <0x58>;
				phandle = <0x58>;
			};

			csi0@1 {
				allwinner,pins = "PD0\0PD2\0PD3\0PD4\0PD5\0PD6\0PD7\0PD8\0PD9\0PD10\0PD11";
				allwinner,pname = "csi0_pck\0csi0_hsync\0csi0_vsync\0csi0_d0\0csi0_d1\0csi0_d2\0csi0_d3\0csi0_d4\0csi0_d5\0csi0_d6\0csi0_d7";
				allwinner,function = "io_disabled";
				allwinner,muxsel = <0x07>;
				allwinner,drive = <0x01>;
				allwinner,pull = <0x00>;
				allwinner,data = <0x00>;
				linux,phandle = <0xa2>;
				phandle = <0xa2>;
			};

			csi_mclk0@0 {
				allwinner,pins = "PD1";
				allwinner,pname = "csi_mclk0";
				allwinner,function = "csi_mclk0";
				allwinner,muxsel = <0x04>;
				allwinner,drive = <0x01>;
				allwinner,pull = <0x00>;
				allwinner,data = <0x00>;
				linux,phandle = <0x9c>;
				phandle = <0x9c>;
			};

			csi_mclk0@1 {
				allwinner,pins = "PD1";
				allwinner,pname = "csi_mclk0";
				allwinner,function = "io_disabled";
				allwinner,muxsel = <0x07>;
				allwinner,drive = <0x01>;
				allwinner,pull = <0x00>;
				allwinner,data = <0x00>;
				linux,phandle = <0x9d>;
				phandle = <0x9d>;
			};

			csi_cci0@0 {
				allwinner,pins = "PD12\0PD13";
				allwinner,pname = "csi_cci0_sck\0csi_cci0_sda";
				allwinner,function = "csi_cci0";
				allwinner,muxsel = <0x04>;
				allwinner,drive = <0x01>;
				allwinner,pull = <0x00>;
				allwinner,data = <0x00>;
				linux,phandle = <0x9f>;
				phandle = <0x9f>;
			};

			csi_cci0@1 {
				allwinner,pins = "PD12\0PD13";
				allwinner,pname = "csi_cci0_sck\0csi_cci0_sda";
				allwinner,function = "io_disabled";
				allwinner,muxsel = <0x07>;
				allwinner,drive = <0x01>;
				allwinner,pull = <0x00>;
				allwinner,data = <0x00>;
				linux,phandle = <0xa0>;
				phandle = <0xa0>;
			};

			scr0@0 {
				allwinner,pins = "PG13\0PG14\0PG10\0PG11\0PG12";
				allwinner,pname = "scr0_rst\0scr0_det\0scr0_vccen\0scr0_sck\0scr0_sda";
				allwinner,function = "sim0";
				allwinner,muxsel = <0x04>;
				allwinner,drive = <0x00>;
				allwinner,pull = <0x01>;
				linux,phandle = <0xaf>;
				phandle = <0xaf>;
			};

			scr0@1 {
				allwinner,pins = "PG8\0PG9";
				allwinner,pname = "scr0_vppen\0scr0_vppp";
				allwinner,function = "sim0";
				allwinner,muxsel = <0x04>;
				allwinner,drive = <0x00>;
				allwinner,pull = <0x01>;
				linux,phandle = <0xb0>;
				phandle = <0xb0>;
			};

			scr0@2 {
				allwinner,pins = "PG8\0PG9\0PG10\0PG11\0PG12\0PG13\0PG14";
				allwinner,function = "io_disabled";
				allwinner,muxsel = <0x07>;
				allwinner,drive = <0x00>;
				allwinner,pull = <0x00>;
				linux,phandle = <0xb1>;
				phandle = <0xb1>;
			};

			scr1@0 {
				allwinner,pins = "PH5\0PH6\0PH2\0PH3\0PH4";
				allwinner,pname = "scr1_rst\0scr1_det\0scr1_vccen\0scr1_sck\0scr1_sda";
				allwinner,function = "sim1";
				allwinner,muxsel = <0x05>;
				allwinner,drive = <0x01>;
				allwinner,pull = <0x01>;
				linux,phandle = <0xb3>;
				phandle = <0xb3>;
			};

			scr1@1 {
				allwinner,pins = "PH0\0PH1";
				allwinner,pname = "scr1_vppen\0scr1_vppp";
				allwinner,function = "sim1";
				allwinner,muxsel = <0x05>;
				allwinner,drive = <0x01>;
				allwinner,pull = <0x01>;
				linux,phandle = <0xb4>;
				phandle = <0xb4>;
			};

			scr1@2 {
				allwinner,pins = "PH0\0PH1\0PH2\0PH3\0PH4\0PH5\0PH6";
				allwinner,function = "io_disabled";
				allwinner,muxsel = <0x07>;
				allwinner,drive = <0x01>;
				allwinner,pull = <0x00>;
				linux,phandle = <0xb5>;
				phandle = <0xb5>;
			};

			nand0@2 {
				allwinner,pins = "PC0\0PC1\0PC2\0PC3\0PC4\0PC5\0PC6\0PC7\0PC8\0PC9\0PC10\0PC11\0PC12\0PC13\0PC14\0PC15\0PC16";
				allwinner,function = "io_disabled";
				allwinner,muxsel = <0x07>;
				allwinner,drive = <0x01>;
				allwinner,pull = <0x00>;
				linux,phandle = <0xba>;
				phandle = <0xba>;
			};

			hdmi@1 {
				allwinner,pins = "PH8\0PH9";
				allwinner,function = "io_disabled";
				allwinner,muxsel = <0x07>;
				allwinner,drive = <0x01>;
				allwinner,pull = <0x00>;
				linux,phandle = <0x90>;
				phandle = <0x90>;
			};

			hdmi@2 {
				allwinner,pins = "PH10";
				allwinner,function = "cec0";
				allwinner,muxsel = <0x02>;
				allwinner,drive = <0x01>;
				allwinner,pull = <0x00>;
				linux,phandle = <0x91>;
				phandle = <0x91>;
			};

			hdmi@3 {
				allwinner,pins = "PH10";
				allwinner,function = "io_disabled";
				allwinner,muxsel = <0x07>;
				allwinner,drive = <0x01>;
				allwinner,pull = <0x00>;
				linux,phandle = <0x92>;
				phandle = <0x92>;
			};

			ac200@2 {
				allwinner,pins = "PB0";
				allwinner,function = "ccir_clk";
				allwinner,muxsel = <0x02>;
				allwinner,drive = <0x01>;
				allwinner,pull = <0x00>;
				linux,phandle = <0x98>;
				phandle = <0x98>;
			};

			ac200@3 {
				allwinner,pins = "PB0";
				allwinner,function = "io_disabled";
				allwinner,muxsel = <0x07>;
				allwinner,drive = <0x01>;
				allwinner,pull = <0x00>;
				linux,phandle = <0x99>;
				phandle = <0x99>;
			};

			card0_boot_para@0 {
				linux,phandle = <0xdd>;
				phandle = <0xdd>;
				allwinner,pins = "PF0\0PF1\0PF2\0PF3\0PF4\0PF5";
				allwinner,function = "card0_boot_para";
				allwinner,pname = "sdc_d1\0sdc_d0\0sdc_clk\0sdc_cmd\0sdc_d3\0sdc_d2";
				allwinner,muxsel = <0x02>;
				allwinner,pull = <0x01>;
				allwinner,drive = <0x02>;
				allwinner,data = <0xffffffff>;
			};

			card2_boot_para@0 {
				linux,phandle = <0xde>;
				phandle = <0xde>;
				allwinner,pins = "PC1\0PC4\0PC5\0PC6\0PC7\0PC8\0PC9\0PC10\0PC11\0PC12\0PC13\0PC14";
				allwinner,function = "card2_boot_para";
				allwinner,pname = "sdc_ds\0sdc_clk\0sdc_cmd\0sdc_d0\0sdc_d1\0sdc_d2\0sdc_d3\0sdc_d4\0sdc_d5\0sdc_d6\0sdc_d7\0sdc_emmc_rst";
				allwinner,muxsel = <0x03>;
				allwinner,pull = <0x01>;
				allwinner,drive = <0x03>;
				allwinner,data = <0xffffffff>;
			};

			uart_para@0 {
				linux,phandle = <0xdf>;
				phandle = <0xdf>;
				allwinner,pins = "PF2\0PF4";
				allwinner,function = "uart_para";
				allwinner,pname = "uart_debug_tx\0uart_debug_rx";
				allwinner,muxsel = <0x03>;
				allwinner,pull = <0x01>;
				allwinner,drive = <0x01>;
				allwinner,data = <0xffffffff>;
			};

			jtag_para@0 {
				linux,phandle = <0xe0>;
				phandle = <0xe0>;
				allwinner,pins = "PF0\0PF5\0PF3\0PF1";
				allwinner,function = "jtag_para";
				allwinner,pname = "jtag_ms\0jtag_ck\0jtag_do\0jtag_di";
				allwinner,muxsel = <0x03>;
				allwinner,pull = <0x01>;
				allwinner,drive = <0x01>;
				allwinner,data = <0xffffffff>;
			};

			gmac0@0 {
				linux,phandle = <0xe1>;
				phandle = <0xe1>;
				allwinner,pins = "PA0\0PA1\0PA2\0PA3\0PA4\0PA5\0PA6\0PA7\0PA8\0PA9";
				allwinner,function = "gmac0";
				allwinner,pname = "gmac_rxd1\0gmac_rxd0\0gmac_crs\0gmac_rxerr\0gmac_txd1\0gmac_txd0\0gmac_txclk\0gmac_txen\0gmac_mdc\0gmac_mdio";
				allwinner,muxsel = <0x02>;
				allwinner,pull = <0xffffffff>;
				allwinner,drive = <0x03>;
				allwinner,data = <0xffffffff>;
			};

			twi0@0 {
				linux,phandle = <0xe2>;
				phandle = <0xe2>;
				allwinner,pins = "PD25\0PD26";
				allwinner,function = "twi0";
				allwinner,pname = "twi0_scl\0twi0_sda";
				allwinner,muxsel = <0x02>;
				allwinner,pull = <0xffffffff>;
				allwinner,drive = <0xffffffff>;
				allwinner,data = <0xffffffff>;
			};

			twi0@1 {
				linux,phandle = <0xe3>;
				phandle = <0xe3>;
				allwinner,pins = "PD25\0PD26";
				allwinner,function = "twi0";
				allwinner,pname = "twi0_scl\0twi0_sda";
				allwinner,muxsel = <0x07>;
				allwinner,pull = <0xffffffff>;
				allwinner,drive = <0xffffffff>;
				allwinner,data = <0xffffffff>;
			};

			twi1@0 {
				linux,phandle = <0xe4>;
				phandle = <0xe4>;
				allwinner,pins = "PH5\0PH6";
				allwinner,function = "twi1";
				allwinner,pname = "twi1_scl\0twi1_sda";
				allwinner,muxsel = <0x04>;
				allwinner,pull = <0xffffffff>;
				allwinner,drive = <0xffffffff>;
				allwinner,data = <0xffffffff>;
			};

			twi1@1 {
				linux,phandle = <0xe5>;
				phandle = <0xe5>;
				allwinner,pins = "PH5\0PH6";
				allwinner,function = "twi1";
				allwinner,pname = "twi1_scl\0twi1_sda";
				allwinner,muxsel = <0x07>;
				allwinner,pull = <0xffffffff>;
				allwinner,drive = <0xffffffff>;
				allwinner,data = <0xffffffff>;
			};

			twi2@0 {
				linux,phandle = <0xe6>;
				phandle = <0xe6>;
				allwinner,pins = "PD23\0PD24";
				allwinner,function = "twi2";
				allwinner,pname = "twi2_scl\0twi2_sda";
				allwinner,muxsel = <0x02>;
				allwinner,pull = <0xffffffff>;
				allwinner,drive = <0xffffffff>;
				allwinner,data = <0xffffffff>;
			};

			twi2@1 {
				linux,phandle = <0xe7>;
				phandle = <0xe7>;
				allwinner,pins = "PD23\0PD24";
				allwinner,function = "twi2";
				allwinner,pname = "twi2_scl\0twi2_sda";
				allwinner,muxsel = <0x07>;
				allwinner,pull = <0xffffffff>;
				allwinner,drive = <0xffffffff>;
				allwinner,data = <0xffffffff>;
			};

			twi3@0 {
				linux,phandle = <0xe8>;
				phandle = <0xe8>;
				allwinner,pins = "PB17\0PB18";
				allwinner,function = "twi3";
				allwinner,pname = "twi3_scl\0twi3_sda";
				allwinner,muxsel = <0x02>;
				allwinner,pull = <0xffffffff>;
				allwinner,drive = <0xffffffff>;
				allwinner,data = <0xffffffff>;
			};

			uart0@0 {
				linux,phandle = <0xe9>;
				phandle = <0xe9>;
				allwinner,pins = "PF2\0PF4";
				allwinner,function = "uart0";
				allwinner,pname = "uart0_tx\0uart0_rx";
				allwinner,muxsel = <0x03>;
				allwinner,pull = <0x01>;
				allwinner,drive = <0x01>;
				allwinner,data = <0xffffffff>;
			};

			uart0@1 {
				linux,phandle = <0xea>;
				phandle = <0xea>;
				allwinner,pins = "PF2\0PF4";
				allwinner,function = "uart0";
				allwinner,pname = "uart0_tx\0uart0_rx";
				allwinner,muxsel = <0x03>;
				allwinner,pull = <0x01>;
				allwinner,drive = <0x01>;
				allwinner,data = <0xffffffff>;
			};

			uart1@0 {
				linux,phandle = <0xeb>;
				phandle = <0xeb>;
				allwinner,pins = "PG6\0PG7\0PG8\0PG9";
				allwinner,function = "uart1";
				allwinner,pname = "uart1_tx\0uart1_rx\0uart1_rts\0uart1_cts";
				allwinner,muxsel = <0x02>;
				allwinner,pull = <0x01>;
				allwinner,drive = <0xffffffff>;
				allwinner,data = <0xffffffff>;
			};

			uart1@1 {
				linux,phandle = <0xec>;
				phandle = <0xec>;
				allwinner,pins = "PG6\0PG7\0PG8\0PG9";
				allwinner,function = "uart1";
				allwinner,pname = "uart1_tx\0uart1_rx\0uart1_rts\0uart1_cts";
				allwinner,muxsel = <0x07>;
				allwinner,pull = <0x01>;
				allwinner,drive = <0xffffffff>;
				allwinner,data = <0xffffffff>;
			};

			uart2@0 {
				linux,phandle = <0xed>;
				phandle = <0xed>;
				allwinner,pins = "PD19\0PD20\0PD21\0PD22";
				allwinner,function = "uart2";
				allwinner,pname = "uart2_tx\0uart2_rx\0uart2_rts\0uart2_cts";
				allwinner,muxsel = <0x04>;
				allwinner,pull = <0x01>;
				allwinner,drive = <0xffffffff>;
				allwinner,data = <0xffffffff>;
			};

			uart2@1 {
				linux,phandle = <0xee>;
				phandle = <0xee>;
				allwinner,pins = "PD19\0PD20\0PD21\0PD22";
				allwinner,function = "uart2";
				allwinner,pname = "uart2_tx\0uart2_rx\0uart2_rts\0uart2_cts";
				allwinner,muxsel = <0x07>;
				allwinner,pull = <0x01>;
				allwinner,drive = <0xffffffff>;
				allwinner,data = <0xffffffff>;
			};

			uart3@0 {
				linux,phandle = <0xef>;
				phandle = <0xef>;
				allwinner,pins = "PD23\0PD24\0PD25\0PD26";
				allwinner,function = "uart3";
				allwinner,pname = "uart3_tx\0uart3_rx\0uart3_rts\0uart3_cts";
				allwinner,muxsel = <0x04>;
				allwinner,pull = <0x01>;
				allwinner,drive = <0xffffffff>;
				allwinner,data = <0xffffffff>;
			};

			uart3@1 {
				linux,phandle = <0xf0>;
				phandle = <0xf0>;
				allwinner,pins = "PD23\0PD24\0PD25\0PD26";
				allwinner,function = "uart3";
				allwinner,pname = "uart3_tx\0uart3_rx\0uart3_rts\0uart3_cts";
				allwinner,muxsel = <0x07>;
				allwinner,pull = <0x01>;
				allwinner,drive = <0xffffffff>;
				allwinner,data = <0xffffffff>;
			};

			spi0@0 {
				linux,phandle = <0xf1>;
				phandle = <0xf1>;
				allwinner,pins = "PC5";
				allwinner,function = "spi0";
				allwinner,pname = "spi0_cs0";
				allwinner,muxsel = <0x04>;
				allwinner,pull = <0x01>;
				allwinner,drive = <0xffffffff>;
				allwinner,data = <0xffffffff>;
			};

			spi0@1 {
				linux,phandle = <0xf2>;
				phandle = <0xf2>;
				allwinner,pins = "PC0\0PC2\0PC3";
				allwinner,function = "spi0";
				allwinner,pname = "spi0_sclk\0spi0_mosi\0spi0_miso";
				allwinner,muxsel = <0x04>;
				allwinner,pull = <0xffffffff>;
				allwinner,drive = <0xffffffff>;
				allwinner,data = <0xffffffff>;
			};

			spi0@2 {
				linux,phandle = <0xf3>;
				phandle = <0xf3>;
				allwinner,pins = "PC5";
				allwinner,function = "spi0";
				allwinner,pname = "spi0_cs0";
				allwinner,muxsel = <0x07>;
				allwinner,pull = <0x01>;
				allwinner,drive = <0xffffffff>;
				allwinner,data = <0xffffffff>;
			};

			spi0@3 {
				linux,phandle = <0xf4>;
				phandle = <0xf4>;
				allwinner,pins = "PC0\0PC2\0PC3";
				allwinner,function = "spi0";
				allwinner,pname = "spi0_sclk\0spi0_mosi\0spi0_miso";
				allwinner,muxsel = <0x07>;
				allwinner,pull = <0xffffffff>;
				allwinner,drive = <0xffffffff>;
				allwinner,data = <0xffffffff>;
			};

			spi1@0 {
				linux,phandle = <0xf5>;
				phandle = <0xf5>;
				allwinner,pins = "PH3";
				allwinner,function = "spi1";
				allwinner,pname = "spi1_cs0";
				allwinner,muxsel = <0x02>;
				allwinner,pull = <0x01>;
				allwinner,drive = <0xffffffff>;
				allwinner,data = <0xffffffff>;
			};

			spi1@1 {
				linux,phandle = <0xf6>;
				phandle = <0xf6>;
				allwinner,pins = "PH4\0PH5\0PH6";
				allwinner,function = "spi1";
				allwinner,pname = "spi1_sclk\0spi1_mosi\0spi1_miso";
				allwinner,muxsel = <0x02>;
				allwinner,pull = <0xffffffff>;
				allwinner,drive = <0xffffffff>;
				allwinner,data = <0xffffffff>;
			};

			spi1@2 {
				linux,phandle = <0xf7>;
				phandle = <0xf7>;
				allwinner,pins = "PH3";
				allwinner,function = "spi1";
				allwinner,pname = "spi1_cs0";
				allwinner,muxsel = <0x07>;
				allwinner,pull = <0x01>;
				allwinner,drive = <0xffffffff>;
				allwinner,data = <0xffffffff>;
			};

			spi1@3 {
				linux,phandle = <0xf8>;
				phandle = <0xf8>;
				allwinner,pins = "PH4\0PH5\0PH6";
				allwinner,function = "spi1";
				allwinner,pname = "spi1_sclk\0spi1_mosi\0spi1_miso";
				allwinner,muxsel = <0x07>;
				allwinner,pull = <0xffffffff>;
				allwinner,drive = <0xffffffff>;
				allwinner,data = <0xffffffff>;
			};

			nand0@0 {
				linux,phandle = <0xfa>;
				phandle = <0xfa>;
				allwinner,pins = "PC0\0PC1\0PC2\0PC4\0PC6\0PC7\0PC8\0PC9\0PC10\0PC11\0PC12\0PC13\0PC14";
				allwinner,function = "nand0";
				allwinner,pname = "nand0_we\0nand0_ale\0nand0_cle\0nand0_nre\0nand0_d0\0nand0_d1\0nand0_d2\0nand0_d3\0nand0_d4\0nand0_d5\0nand0_d6\0nand0_d7\0nand0_ndqs";
				allwinner,muxsel = <0x02>;
				allwinner,pull = <0x00>;
				allwinner,drive = <0x01>;
				allwinner,data = <0xffffffff>;
			};

			nand0@1 {
				linux,phandle = <0xfb>;
				phandle = <0xfb>;
				allwinner,pins = "PC15\0PC3\0PC5\0PC16";
				allwinner,function = "nand0";
				allwinner,pname = "nand0_ce1\0nand0_ce0\0nand0_rb0\0nand0_rb1";
				allwinner,muxsel = <0x02>;
				allwinner,pull = <0x01>;
				allwinner,drive = <0x01>;
				allwinner,data = <0xffffffff>;
			};

			lcd0@0 {
				linux,phandle = <0xfc>;
				phandle = <0xfc>;
				allwinner,pins = "PD0\0PD1\0PD2\0PD3\0PD4\0PD5\0PD6\0PD7\0PD8\0PD9\0PD10\0PD11\0PD12\0PD13\0PD14\0PD15\0PD16\0PD17\0PD18\0PD19\0PD20\0PD21";
				allwinner,function = "lcd0";
				allwinner,pname = "lcdd0\0lcdd1\0lcdd2\0lcdd3\0lcdd4\0lcdd5\0lcdd6\0lcdd7\0lcdd8\0lcdd9\0lcdd10\0lcdd11\0lcdd12\0lcdd13\0lcdd14\0lcdd15\0lcdd16\0lcdd17\0lcdd18\0lcdd19\0lcdd20\0lcdd21";
				allwinner,muxsel = <0x02>;
				allwinner,pull = <0x00>;
				allwinner,drive = <0xffffffff>;
				allwinner,data = <0xffffffff>;
			};

			lcd0@1 {
				linux,phandle = <0xfd>;
				phandle = <0xfd>;
				allwinner,pins = "PD0\0PD1\0PD2\0PD3\0PD4\0PD5\0PD6\0PD7\0PD8\0PD9\0PD10\0PD11\0PD12\0PD13\0PD14\0PD15\0PD16\0PD17\0PD18\0PD19\0PD20\0PD21";
				allwinner,function = "lcd0";
				allwinner,pname = "lcdd0\0lcdd1\0lcdd2\0lcdd3\0lcdd4\0lcdd5\0lcdd6\0lcdd7\0lcdd8\0lcdd9\0lcdd10\0lcdd11\0lcdd12\0lcdd13\0lcdd14\0lcdd15\0lcdd16\0lcdd17\0lcdd18\0lcdd19\0lcdd20\0lcdd21";
				allwinner,muxsel = <0x07>;
				allwinner,pull = <0x00>;
				allwinner,drive = <0xffffffff>;
				allwinner,data = <0xffffffff>;
			};

			hdmi@0 {
				linux,phandle = <0xfe>;
				phandle = <0xfe>;
				allwinner,pins = "PH8\0PH9\0PH10";
				allwinner,function = "hdmi";
				allwinner,pname = "ddc_scl\0ddc_sda\0cec_io";
				allwinner,muxsel = <0x02>;
				allwinner,pull = <0xffffffff>;
				allwinner,drive = <0x01>;
				allwinner,data = <0xffffffff>;
			};

			ac200@0 {
				linux,phandle = <0xff>;
				phandle = <0xff>;
				allwinner,pins = "PB0\0PB1\0PB2\0PB3\0PB4\0PB5\0PB6\0PB7\0PB8\0PB9\0PB10\0PB11";
				allwinner,function = "ac200";
				allwinner,pname = "ccir_clk\0ccir_de\0ccir_hs\0ccir_vs\0ccir_do0\0ccir_do1\0ccir_do2\0ccir_do3\0ccir_do4\0ccir_do5\0ccir_do6\0ccir_do7";
				allwinner,muxsel = <0x02>;
				allwinner,pull = <0x00>;
				allwinner,drive = <0xffffffff>;
				allwinner,data = <0xffffffff>;
			};

			ac200@1 {
				linux,phandle = <0x100>;
				phandle = <0x100>;
				allwinner,pins = "PB1\0PB2\0PB3\0PB4\0PB5\0PB6\0PB7\0PB8\0PB9\0PB10\0PB11";
				allwinner,function = "ac200";
				allwinner,pname = "ccir_de\0ccir_hs\0ccir_vs\0ccir_do0\0ccir_do1\0ccir_do2\0ccir_do3\0ccir_do4\0ccir_do5\0ccir_do6\0ccir_do7";
				allwinner,muxsel = <0x07>;
				allwinner,pull = <0x00>;
				allwinner,drive = <0xffffffff>;
				allwinner,data = <0xffffffff>;
			};

			pwm0@0 {
				linux,phandle = <0x101>;
				phandle = <0x101>;
				allwinner,pins = "PD22";
				allwinner,function = "pwm0";
				allwinner,pname = "pwm_positive";
				allwinner,muxsel = <0x02>;
				allwinner,pull = <0x00>;
				allwinner,drive = <0xffffffff>;
				allwinner,data = <0xffffffff>;
			};

			pwm0@1 {
				linux,phandle = <0x102>;
				phandle = <0x102>;
				allwinner,pins = "PD22";
				allwinner,function = "pwm0";
				allwinner,pname = "pwm_positive";
				allwinner,muxsel = <0x07>;
				allwinner,pull = <0x00>;
				allwinner,drive = <0xffffffff>;
				allwinner,data = <0xffffffff>;
			};

			pwm1@0 {
				linux,phandle = <0x103>;
				phandle = <0x103>;
				allwinner,pins = "PB19";
				allwinner,function = "pwm1";
				allwinner,pname = "pwm_positive";
				allwinner,muxsel = <0x02>;
				allwinner,pull = <0x00>;
				allwinner,drive = <0xffffffff>;
				allwinner,data = <0xffffffff>;
			};

			pwm1@1 {
				linux,phandle = <0x104>;
				phandle = <0x104>;
				allwinner,pins = "PB19";
				allwinner,function = "pwm1";
				allwinner,pname = "pwm_positive";
				allwinner,muxsel = <0x07>;
				allwinner,pull = <0x00>;
				allwinner,drive = <0xffffffff>;
				allwinner,data = <0xffffffff>;
			};

			csi0@0 {
				linux,phandle = <0x107>;
				phandle = <0x107>;
				allwinner,pins = "PD0\0PD2\0PD3\0PD4\0PD5\0PD6\0PD7\0PD8\0PD9\0PD10\0PD11\0PD12\0PD13";
				allwinner,function = "csi0";
				allwinner,pname = "csi0_pck\0csi0_hsync\0csi0_vsync\0csi0_d0\0csi0_d1\0csi0_d2\0csi0_d3\0csi0_d4\0csi0_d5\0csi0_d6\0csi0_d7\0csi0_sck\0csi0_sda";
				allwinner,muxsel = <0x04>;
				allwinner,pull = <0xffffffff>;
				allwinner,drive = <0xffffffff>;
				allwinner,data = <0xffffffff>;
			};

			csi0@2 {
				linux,phandle = <0x108>;
				phandle = <0x108>;
				allwinner,pins = "PD1";
				allwinner,function = "csi0";
				allwinner,pname = "csi0_mck";
				allwinner,muxsel = <0x04>;
				allwinner,pull = <0x00>;
				allwinner,drive = <0x01>;
				allwinner,data = <0x00>;
			};

			sdc0@0 {
				linux,phandle = <0x109>;
				phandle = <0x109>;
				allwinner,pins = "PF0\0PF1\0PF2\0PF3\0PF4\0PF5";
				allwinner,function = "sdc0";
				allwinner,pname = "sdc0_d1\0sdc0_d0\0sdc0_clk\0sdc0_cmd\0sdc0_d3\0sdc0_d2";
				allwinner,muxsel = <0x02>;
				allwinner,pull = <0x01>;
				allwinner,drive = <0x02>;
				allwinner,data = <0xffffffff>;
			};

			sdc1@0 {
				linux,phandle = <0x10a>;
				phandle = <0x10a>;
				allwinner,pins = "PG0\0PG1\0PG2\0PG3\0PG4\0PG5";
				allwinner,function = "sdc1";
				allwinner,pname = "sdc1_clk\0sdc1_cmd\0sdc1_d0\0sdc1_d1\0sdc1_d2\0sdc1_d3";
				allwinner,muxsel = <0x02>;
				allwinner,pull = <0x01>;
				allwinner,drive = <0x03>;
				allwinner,data = <0xffffffff>;
			};

			sdc2@0 {
				linux,phandle = <0x10b>;
				phandle = <0x10b>;
				allwinner,pins = "PC1\0PC4\0PC5\0PC6\0PC7\0PC8\0PC9\0PC10\0PC11\0PC12\0PC13\0PC14";
				allwinner,function = "sdc2";
				allwinner,pname = "sdc2_ds\0sdc2_clk\0sdc2_cmd\0sdc2_d0\0sdc2_d1\0sdc2_d2\0sdc2_d3\0sdc2_d4\0sdc2_d5\0sdc2_d6\0sdc2_d7\0sdc2_emmc_rst";
				allwinner,muxsel = <0x03>;
				allwinner,pull = <0x01>;
				allwinner,drive = <0x03>;
				allwinner,data = <0xffffffff>;
			};

			Vdevice@0 {
				linux,phandle = <0x10f>;
				phandle = <0x10f>;
				allwinner,pins = "PH9\0PH10";
				allwinner,function = "Vdevice";
				allwinner,pname = "Vdevice_0\0Vdevice_1";
				allwinner,muxsel = <0x05>;
				allwinner,pull = <0x01>;
				allwinner,drive = <0x02>;
				allwinner,data = <0xffffffff>;
			};
		};

		dma-controller@03002000 {
			compatible = "allwinner,sun50i-dma";
			reg = <0x00 0x3002000 0x00 0x1000>;
			interrupts = <0x00 0x2b 0x04>;
			clocks = <0x0c>;
			#dma-cells = <0x01>;
		};

		mbus-controller@04002000 {
			compatible = "allwinner,sun50i-mbus";
			reg = <0x00 0x4002000 0x00 0x1000>;
			#mbus-cells = <0x01>;
		};

		arisc {
			compatible = "allwinner,sunxi-arisc";
			#address-cells = <0x02>;
			#size-cells = <0x02>;
			clocks = <0x0d 0x0e 0x07 0x02>;
			clock-names = "losc\0iosc\0hosc\0pll_periph0";
			powchk_used = <0x00>;
			power_reg = <0x2309621>;
			system_power = <0x32>;
		};

		arisc_space {
			compatible = "allwinner,arisc_space";
			space1 = <0x48040000 0x00 0x14000>;
			space2 = <0x48100000 0x18000 0x4000>;
			space3 = <0x48104000 0x00 0x1000>;
			space4 = <0x48105000 0x00 0x1000>;
		};

		standby_space {
			compatible = "allwinner,standby_space";
			space1 = <0x40020000 0x00 0x800>;
		};

		msgbox@03003000 {
			compatible = "allwinner,msgbox";
			clocks = <0x0f>;
			clock-names = "clk_msgbox";
			reg = <0x00 0x3003000 0x00 0x1000>;
			interrupts = <0x00 0x27 0x01>;
			status = "okay";
		};

		hwspinlock@3004000 {
			compatible = "allwinner,sunxi-hwspinlock";
			clocks = <0x10 0x11>;
			clock-names = "clk_hwspinlock_rst\0clk_hwspinlock_bus";
			reg = <0x00 0x3004000 0x00 0x1000>;
			num-locks = <0x08>;
			status = "okay";
		};

		s_cir@07040000 {
			compatible = "allwinner,s_cir";
			reg = <0x00 0x7040000 0x00 0x400>;
			interrupts = <0x00 0x6d 0x04>;
			pinctrl-names = "default";
			pinctrl-0 = <0x12>;
			clocks = <0x07 0x13>;
			supply = [00];
			supply_vol = [00];
			status = "okay";
			device_type = "s_cir0";
			ir_protocol_used = <0x00>;
			ir_power_key_code0 = <0xdc>;
			ir_addr_code0 = <0xfd01>;
			rc5_ir_power_key_code0 = <0x01>;
			rc5_ir_addr_code0 = <0x04>;
		};

		s_uart@7080000 {
			compatible = "allwinner,s_uart";
			reg = <0x00 0x7080000 0x00 0xd0>;
			interrupts = <0x00 0x6a 0x04>;
			pinctrl-names = "default";
			status = "disabled";
			device_type = "s_uart0";
			pinctrl-0 = <0x10c>;
		};

		s_twi@1f03400 {
			compatible = "allwinner,s_twi";
			reg = <0x00 0x1f02400 0x00 0x20>;
			interrupts = <0x00 0x2c 0x04>;
			pinctrl-names = "default";
			status = "disabled";
			device_type = "s_twi0";
			pinctrl-0 = <0x10d>;
		};

		s_jtag0 {
			compatible = "allwinner,s_jtag";
			pinctrl-names = "default";
			status = "disabled";
			device_type = "s_jtag0";
			pinctrl-0 = <0x10e>;
		};

		box_start_os0 {
			compatible = "allwinner,box_start_os";
			start_type = <0x01>;
			irkey_used = <0x01>;
			pmukey_used = <0x00>;
			pmukey_num = <0x00>;
			led_power = <0x00>;
			led_state = <0x00>;
			status = "okay";
			device_type = "box_start_os";
		};

		timer@03009000 {
			compatible = "allwinner,sunxi-timer";
			device_type = "timer";
			reg = <0x00 0x3009000 0x00 0x400>;
			interrupts = <0x00 0x30 0x04>;
			clock-frequency = <0x16e3600>;
			timer-prescale = <0x10>;
		};

		rtc@07000000 {
			compatible = "allwinner,sun50iw6-rtc";
			device_type = "rtc";
			reg = <0x00 0x7000000 0x00 0x200>;
			interrupts = <0x00 0x65 0x04>;
			gpr_offset = <0x100>;
			gpr_len = <0x08>;
		};

		watchdog@030090a0 {
			compatible = "allwinner,sun50i-wdt";
			reg = <0x00 0x30090a0 0x00 0x20>;
			interrupts = <0x00 0x32 0x04>;
		};

		ve@01c0e000 {
			compatible = "allwinner,sunxi-cedar-ve";
			reg = <0x00 0x1c0e000 0x00 0x1000 0x00 0x3000000 0x00 0x10 0x00 0x3001000 0x00 0x1000>;
			interrupts = <0x00 0x59 0x04>;
			clocks = <0x17 0x18>;
			iommus = <0x19 0x03 0x01>;
		};

		vp9@01c00000 {
			compatible = "allwinner,sunxi-google-vp9";
			reg = <0x00 0x1c00000 0x00 0x1000 0x00 0x3000000 0x00 0x10 0x00 0x3001000 0x00 0x1000>;
			interrupts = <0x00 0x5a 0x04>;
			clocks = <0x17 0x1a>;
			#clocks = <0x1b 0x1a>;
			iommus = <0x19 0x05 0x01>;
		};

		uart@05000000 {
			compatible = "allwinner,sun50i-uart";
			device_type = "uart0";
			reg = <0x00 0x5000000 0x00 0x400>;
			interrupts = <0x00 0x00 0x04>;
			clocks = <0x1c>;
			pinctrl-names = "default\0sleep";
			uart0_port = <0x00>;
			uart0_type = <0x02>;
			status = "okay";
			pinctrl-0 = <0xe9>;
			pinctrl-1 = <0xea>;
		};

		uart@05000400 {
			compatible = "allwinner,sun50i-uart";
			device_type = "uart1";
			reg = <0x00 0x5000400 0x00 0x400>;
			interrupts = <0x00 0x01 0x04>;
			clocks = <0x1f>;
			pinctrl-names = "default\0sleep";
			uart1_port = <0x01>;
			uart1_type = <0x04>;
			status = "okay";
			pinctrl-0 = <0xeb>;
			uart1_bt = <0x01>;
			pinctrl-1 = <0xec>;
		};

		uart@05000800 {
			compatible = "allwinner,sun50i-uart";
			device_type = "uart2";
			reg = <0x00 0x5000800 0x00 0x400>;
			interrupts = <0x00 0x02 0x04>;
			clocks = <0x22>;
			pinctrl-names = "default\0sleep";
			uart2_port = <0x02>;
			uart2_type = <0x04>;
			status = "disabled";
			pinctrl-0 = <0xed>;
			pinctrl-1 = <0xee>;
		};

		uart@05000c00 {
			compatible = "allwinner,sun50i-uart";
			device_type = "uart3";
			reg = <0x00 0x5000c00 0x00 0x400>;
			interrupts = <0x00 0x03 0x04>;
			clocks = <0x25>;
			pinctrl-names = "default\0sleep";
			uart3_port = <0x03>;
			uart3_type = <0x04>;
			status = "disabled";
			pinctrl-0 = <0xef>;
			pinctrl-1 = <0xf0>;
		};

		twi@0x05002000 {
			#address-cells = <0x01>;
			#size-cells = <0x00>;
			compatible = "allwinner,sun50i-twi";
			device_type = "twi0";
			reg = <0x00 0x5002000 0x00 0x400>;
			interrupts = <0x00 0x04 0x04>;
			clocks = <0x28>;
			clock-frequency = <0x61a80>;
			pinctrl-names = "default\0sleep";
			status = "disabled";
			pinctrl-0 = <0xe2>;
			pinctrl-1 = <0xe3>;
		};

		twi@0x05002400 {
			#address-cells = <0x01>;
			#size-cells = <0x00>;
			compatible = "allwinner,sun50i-twi";
			device_type = "twi1";
			reg = <0x00 0x5002400 0x00 0x400>;
			interrupts = <0x00 0x05 0x04>;
			clocks = <0x2b>;
			clock-frequency = <0x30d40>;
			pinctrl-names = "default\0sleep";
			status = "disabled";
			pinctrl-0 = <0xe4>;
			pinctrl-1 = <0xe5>;
		};

		twi@0x05002800 {
			#address-cells = <0x01>;
			#size-cells = <0x00>;
			compatible = "allwinner,sun50i-twi";
			device_type = "twi2";
			reg = <0x00 0x5002800 0x00 0x400>;
			interrupts = <0x00 0x06 0x04>;
			clocks = <0x2e>;
			clock-frequency = <0x30d40>;
			pinctrl-names = "default\0sleep";
			status = "disabled";
			pinctrl-0 = <0xe6>;
			pinctrl-1 = <0xe7>;
		};

		twi@0x05002c00 {
			#address-cells = <0x01>;
			#size-cells = <0x00>;
			compatible = "allwinner,sun50i-twi";
			device_type = "twi3";
			reg = <0x00 0x5002c00 0x00 0x400>;
			interrupts = <0x00 0x07 0x04>;
			clocks = <0x31>;
			clock-frequency = <0x30d40>;
			pinctrl-names = "default\0sleep";
			pinctrl-1 = <0x33>;
			status = "okay";
			pinctrl-0 = <0xe8>;
		};

		usbc0@0 {
			device_type = "usbc0";
			compatible = "allwinner,sunxi-otg-manager";
			usb_port_type = <0x01>;
			usb_detect_type = <0x01>;
			usb_host_init_state = <0x01>;
			usb_regulator_io = "nocare";
			usb_wakeup_suspend = <0x00>;
			usb_luns = <0x03>;
			usb_serial_unique = <0x00>;
			usb_serial_number = "20080411";
			rndis_wceis = <0x01>;
			status = "okay";
			usb_detect_mode = <0x00>;
			usb_id_gpio;
			usb_det_vbus_gpio;
			usb_drv_vbus_gpio;
		};

		udc-controller@0x05100000 {
			compatible = "allwinner,sunxi-udc";
			reg = <0x00 0x5100000 0x00 0x1000 0x00 0x00 0x00 0x100>;
			interrupts = <0x00 0x17 0x04>;
			clocks = <0x34 0x35>;
			status = "okay";
		};

		ehci0-controller@0x05101000 {
			compatible = "allwinner,sunxi-ehci0";
			reg = <0x00 0x5101000 0x00 0xfff 0x00 0x00 0x00 0x100 0x00 0x5100000 0x00 0x1000>;
			interrupts = <0x00 0x18 0x04>;
			clocks = <0x34 0x36>;
			hci_ctrl_no = <0x00>;
			status = "okay";
		};

		ohci0-controller@0x05101400 {
			compatible = "allwinner,sunxi-ohci0";
			reg = <0x00 0x5101000 0x00 0xfff 0x00 0x00 0x00 0x100 0x00 0x5100000 0x00 0x1000>;
			interrupts = <0x00 0x19 0x04>;
			clocks = <0x34 0x37 0x38 0x39 0x07 0x0d>;
			hci_ctrl_no = <0x00>;
			status = "okay";
		};

		usbc1@0 {
			device_type = "usbc1";
			usb_host_init_state = <0x01>;
			usb_regulator_io = "nocare";
			usb_wakeup_suspend = <0x00>;
			status = "okay";
			usb_drv_vbus_gpio = <0xdc 0x0b 0x05 0x01 0x00 0xffffffff 0x01>;
		};

		xhci-controller@0x05200000 {
			compatible = "allwinner,sunxi-xhci";
			reg = <0x00 0x5200000 0x00 0xfffff 0x00 0x00 0x00 0x100 0x00 0x5100000 0x00 0x1000>;
			interrupts = <0x00 0x1a 0x04>;
			clocks = <0x3a 0x3b>;
			hci_ctrl_no = <0x01>;
			status = "okay";
		};

		usbc2@0 {
			device_type = "usbc2";
			usb_host_init_state = <0x01>;
			usb_regulator_io = "nocare";
			usb_wakeup_suspend = <0x00>;
			status = "disabled";
			usb_drv_vbus_gpio;
		};

		ehci3-controller@0x05311000 {
			compatible = "allwinner,sunxi-ehci3";
			reg = <0x00 0x5311000 0x00 0xfff 0x00 0x00 0x00 0x100 0x00 0x5100000 0x00 0x1000>;
			interrupts = <0x00 0x1c 0x04>;
			clocks = <0x3c 0x3d 0x3e 0x3e 0x3f>;
			hci_ctrl_no = <0x03>;
			status = "okay";
		};

		ohci3-controller@0x05311400 {
			compatible = "allwinner,sunxi-ohci3";
			reg = <0x00 0x5311000 0x00 0xfff 0x00 0x00 0x00 0x100 0x00 0x5100000 0x00 0x1000>;
			interrupts = <0x00 0x1d 0x04>;
			clocks = <0x3c 0x40 0x41 0x39 0x07 0x0d>;
			hci_ctrl_no = <0x03>;
			status = "okay";
		};

		ac200_codec {
			compatible = "allwinner,ac200_codec";
			status = "okay";
			device_type = "ac200_codec";
			gpio-spk = <0xdc 0x0b 0x06 0x01 0x01 0xffffffff 0xffffffff>;
		};

		daudio@0x05090000 {
			compatible = "allwinner,sunxi-daudio";
			reg = <0x00 0x5090000 0x00 0x74>;
			clocks = <0x04 0x42>;
			pinctrl-names = "default\0sleep";
			pinctrl-0 = <0x43>;
			pinctrl-1 = <0x44>;
			pcm_lrck_period = <0x20>;
			slot_width_select = <0x20>;
			daudio_master = <0x04>;
			audio_format = <0x01>;
			signal_inversion = <0x01>;
			tdm_config = <0x01>;
			frametype = <0x00>;
			tdm_num = <0x00>;
			mclk_div = <0x00>;
			status = "disabled";
			linux,phandle = <0x59>;
			phandle = <0x59>;
			device_type = "daudio0";
		};

		daudio@0x05091000 {
			compatible = "allwinner,sunxi-tdmhdmi";
			reg = <0x00 0x5091000 0x00 0x74>;
			clocks = <0x04 0x45>;
			status = "okay";
			linux,phandle = <0x5b>;
			phandle = <0x5b>;
			device_type = "audiohdmi";
		};

		daudio@0x05092000 {
			compatible = "allwinner,sunxi-daudio";
			reg = <0x00 0x5092000 0x00 0x74>;
			clocks = <0x04 0x46>;
			pinctrl-names = "default\0sleep";
			pinctrl-0 = <0x47>;
			pinctrl-1 = <0x48>;
			pcm_lrck_period = <0x40>;
			slot_width_select = <0x20>;
			daudio_master = <0x04>;
			audio_format = <0x04>;
			signal_inversion = <0x03>;
			tdm_config = <0x01>;
			frametype = <0x00>;
			tdm_num = <0x02>;
			mclk_div = <0x01>;
			status = "okay";
			linux,phandle = <0x5d>;
			phandle = <0x5d>;
			device_type = "daudio2";
		};

		daudio@0x0508f000 {
			compatible = "allwinner,sunxi-daudio";
			reg = <0x00 0x508f000 0x00 0x74>;
			clocks = <0x04 0x49>;
			pinctrl-names = "default\0sleep";
			pinctrl-0 = <0x4a>;
			pinctrl-1 = <0x4b>;
			pcm_lrck_period = <0x20>;
			slot_width_select = <0x20>;
			daudio_master = <0x04>;
			audio_format = <0x01>;
			signal_inversion = <0x01>;
			tdm_config = <0x01>;
			frametype = <0x00>;
			tdm_num = <0x03>;
			mclk_div = <0x01>;
			status = "okay";
			linux,phandle = <0x5f>;
			phandle = <0x5f>;
			device_type = "daudio3";
		};

		spdif-controller@0x05093000 {
			compatible = "allwinner,sunxi-spdif";
			reg = <0x00 0x5093000 0x00 0x40>;
			clocks = <0x04 0x4c>;
			pinctrl-names = "default\0sleep";
			pinctrl-0 = <0x4d>;
			pinctrl-1 = <0x4e>;
			status = "okay";
			linux,phandle = <0x61>;
			phandle = <0x61>;
			device_type = "spdif";
		};

		dmic-controller@0x05095000 {
			compatible = "allwinner,sunxi-dmic";
			reg = <0x00 0x5095000 0x00 0x50>;
			clocks = <0x04 0x4f>;
			pinctrl-names = "default\0sleep";
			pinctrl-0 = <0x50>;
			pinctrl-1 = <0x51>;
			status = "disabled";
			linux,phandle = <0x62>;
			phandle = <0x62>;
			device_type = "dmic";
		};

		cpudai0-controller@0x05097000 {
			compatible = "allwinner,sunxi-ahub-cpudai";
			reg = <0x00 0x5097000 0x00 0xadf>;
			id = <0x00>;
			status = "okay";
			linux,phandle = <0x63>;
			phandle = <0x63>;
		};

		cpudai1-controller@0x05097000 {
			compatible = "allwinner,sunxi-ahub-cpudai";
			reg = <0x00 0x5097000 0x00 0xadf>;
			id = <0x01>;
			status = "okay";
			linux,phandle = <0x64>;
			phandle = <0x64>;
		};

		cpudai2-controller@0x05097000 {
			compatible = "allwinner,sunxi-ahub-cpudai";
			reg = <0x00 0x5097000 0x00 0xadf>;
			id = <0x02>;
			status = "okay";
			linux,phandle = <0x65>;
			phandle = <0x65>;
		};

		ahub_codec@0x05097000 {
			compatible = "allwinner,sunxi-ahub";
			reg = <0x00 0x5097000 0x00 0xadf>;
			clocks = <0x04 0x52>;
			status = "okay";
			linux,phandle = <0x66>;
			phandle = <0x66>;
		};

		ahub_daudio0@0x05097000 {
			compatible = "allwinner,sunxi-ahub-daudio";
			reg = <0x00 0x5097000 0x00 0xadf>;
			clocks = <0x04 0x52>;
			pinctrl-names = "default\0sleep";
			pinctrl-0 = <0x53>;
			pinctrl-1 = <0x54>;
			pinconfig = <0x01>;
			frametype = <0x00>;
			pcm_lrck_period = <0x20>;
			slot_width_select = <0x20>;
			daudio_master = <0x04>;
			audio_format = <0x01>;
			signal_inversion = <0x01>;
			tdm_config = <0x01>;
			tdm_num = <0x00>;
			mclk_div = <0x00>;
			status = "disabled";
			linux,phandle = <0x5a>;
			phandle = <0x5a>;
			device_type = "ahub_daudio0";
		};

		ahub_daudio1@0x05097000 {
			compatible = "allwinner,sunxi-ahub-daudio";
			reg = <0x00 0x5097000 0x00 0xadf>;
			clocks = <0x04 0x52>;
			pinconfig = <0x00>;
			frametype = <0x00>;
			pcm_lrck_period = <0x20>;
			slot_width_select = <0x20>;
			daudio_master = <0x04>;
			audio_format = <0x01>;
			signal_inversion = <0x01>;
			tdm_config = <0x01>;
			tdm_num = <0x01>;
			mclk_div = <0x01>;
			status = "okay";
			linux,phandle = <0x5c>;
			phandle = <0x5c>;
			device_type = "ahub_daudio1";
		};

		ahub_daudio2@0x05097000 {
			compatible = "allwinner,sunxi-ahub-daudio";
			reg = <0x00 0x5097000 0x00 0xadf>;
			clocks = <0x04 0x52>;
			pinctrl-names = "default\0sleep";
			pinctrl-0 = <0x55>;
			pinctrl-1 = <0x56>;
			pinconfig = <0x01>;
			frametype = <0x00>;
			pcm_lrck_period = <0x20>;
			slot_width_select = <0x20>;
			daudio_master = <0x04>;
			audio_format = <0x01>;
			signal_inversion = <0x01>;
			tdm_config = <0x01>;
			tdm_num = <0x02>;
			mclk_div = <0x01>;
			status = "okay";
			linux,phandle = <0x5e>;
			phandle = <0x5e>;
			device_type = "ahub_daudio2";
		};

		ahub_daudio3@0x05097000 {
			compatible = "allwinner,sunxi-ahub-daudio";
			reg = <0x00 0x5097000 0x00 0xadf>;
			clocks = <0x04 0x52>;
			pinctrl-names = "default\0sleep";
			pinctrl-0 = <0x57>;
			pinctrl-1 = <0x58>;
			pinconfig = <0x01>;
			frametype = <0x00>;
			pcm_lrck_period = <0x20>;
			slot_width_select = <0x20>;
			daudio_master = <0x04>;
			audio_format = <0x01>;
			signal_inversion = <0x01>;
			tdm_config = <0x01>;
			tdm_num = <0x03>;
			mclk_div = <0x04>;
			status = "okay";
			linux,phandle = <0x60>;
			phandle = <0x60>;
			device_type = "ahub_daudio3";
		};

		sound@0 {
			compatible = "allwinner,sunxi-daudio0-machine";
			sunxi,daudio-controller = <0x59>;
			sunxi,cpudai-controller = <0x5a>;
			status = "disabled";
			device_type = "snddaudio0";
		};

		sound@1 {
			compatible = "allwinner,sunxi-hdmi-machine";
			sunxi,hdmi-controller = <0x5b>;
			sunxi,cpudai-controller = <0x5c>;
			status = "okay";
			device_type = "sndhdmi";
		};

		sound@2 {
			compatible = "allwinner,sunxi-daudio2-machine";
			sunxi,daudio-controller = <0x5d>;
			sunxi,cpudai-controller = <0x5e>;
			status = "okay";
			device_type = "snddaudio2";
		};

		sound@3 {
			compatible = "allwinner,sunxi-daudio3-machine";
			sunxi,daudio-controller = <0x5f>;
			sunxi,cpudai-controller = <0x60>;
			sunxi,snddaudio-codec = "acx00-codec";
			sunxi,snddaudio-codec-dai = "acx00-dai";
			status = "okay";
			device_type = "snddaudio3";
		};

		sound@4 {
			compatible = "allwinner,sunxi-spdif-machine";
			sunxi,spdif-controller = <0x61>;
			status = "okay";
			device_type = "sndspdif";
		};

		sound@5 {
			compatible = "allwinner,sunxi-dmic-machine";
			sunxi,dmic-controller = <0x62>;
			status = "disabled";
			device_type = "snddmic";
		};

		sound@6 {
			compatible = "allwinner,sunxi-ahub-machine";
			sunxi,cpudai-controller0 = <0x63>;
			sunxi,cpudai-controller1 = <0x64>;
			sunxi,cpudai-controller2 = <0x65>;
			sunxi,audio-codec = <0x66>;
			status = "okay";
			device_type = "sndahub";
		};

		spi@05010000 {
			#address-cells = <0x01>;
			#size-cells = <0x00>;
			compatible = "allwinner,sun50i-spi";
			device_type = "spi0";
			reg = <0x00 0x5010000 0x00 0x1000>;
			interrupts = <0x00 0x0a 0x04>;
			clocks = <0x02 0x67>;
			clock-frequency = <0x5f5e100>;
			pinctrl-names = "default\0sleep";
			spi0_cs_number = <0x01>;
			spi0_cs_bitmap = <0x01>;
			status = "disabled";
			pinctrl-0 = <0xf1 0xf2>;
			pinctrl-1 = <0xf3 0xf4>;
		};

		spi@05011000 {
			#address-cells = <0x01>;
			#size-cells = <0x00>;
			compatible = "allwinner,sun50i-spi";
			device_type = "spi1";
			reg = <0x00 0x5011000 0x00 0x1000>;
			interrupts = <0x00 0x0b 0x04>;
			clocks = <0x02 0x6b>;
			clock-frequency = <0x5f5e100>;
			pinctrl-names = "default\0sleep";
			spi1_cs_number = <0x01>;
			spi1_cs_bitmap = <0x01>;
			status = "disabled";
			pinctrl-0 = <0xf5 0xf6>;
			pinctrl-1 = <0xf7 0xf8>;
		};

		pcie@0x05400000 {
			#address-cells = <0x03>;
			#size-cells = <0x02>;
			compatible = "allwinner,sun50i-pcie";
			reg = <0x00 0x5400000 0x00 0x2000 0x00 0x5410000 0x00 0x10000>;
			reg-names = "dbi\0config";
			device_type = "pci";
			ranges = <0x800 0x00 0x5410000 0x00 0x5410000 0x00 0x10000 0x81000000 0x00 0x00 0x00 0x5e00000 0x00 0x10000 0x82000000 0x00 0x5500000 0x00 0x5500000 0x00 0x800000>;
			num-lanes = <0x01>;
			interrupts = <0x00 0x7f 0x04 0x00 0x7e 0x04>;
			interrupt-names = "msi";
			clocks = <0x6f 0x70 0x71 0x72 0x73 0x74>;
			#interrupt-cells = <0x01>;
			interrupt-map-mask = <0x00 0x00 0x00 0x00>;
			interrupt-map = <0x00 0x00 0x00 0x01 0x01 0x00 0x7f 0x04>;
			status = "disabled";
			pcie_rest = <0x81 0x07 0x03 0x01 0xffffffff 0xffffffff 0xffffffff>;
			pcie_power = <0xdc 0x0b 0x08 0x01 0xffffffff 0xffffffff 0xffffffff>;
			pcie_reg = <0xdc 0x0c 0x03 0x01 0xffffffff 0xffffffff 0xffffffff>;
			pcie_iodvdd = <0x708>;
			pcie_speed_gen = <0x02>;
			pcie_vdd = "vdd-pcie";
			pcie_vdd_vol = <0xdbba0>;
			pcie_vcc = "vcc-pcie";
			pcie_vcc_vol = <0x1b7740>;
			pcie_vcc_slot = "vcc-pcie-slot";
			pcie_vcc_slot_vol = <0x325aa0>;
		};

		sdmmc@04022000 {
			compatible = "allwinner,sunxi-mmc-v4p6x";
			device_type = "sdc2";
			reg = <0x00 0x4022000 0x00 0x1000>;
			interrupts = <0x00 0x25 0x104>;
			clocks = <0x07 0x75 0x76 0x77 0x78>;
			clock-names = "osc24m\0pll_periph\0mmc\0ahb\0rst";
			pinctrl-names = "default\0sleep";
			pinctrl-1 = <0x7a>;
			bus-width = <0x08>;
			max-frequency = <0x8f0d180>;
			sdc_tm4_sm0_freq0 = <0x00>;
			sdc_tm4_sm0_freq1 = <0x00>;
			sdc_tm4_sm1_freq0 = <0x00>;
			sdc_tm4_sm1_freq1 = <0x00>;
			sdc_tm4_sm2_freq0 = <0x00>;
			sdc_tm4_sm2_freq1 = <0x00>;
			sdc_tm4_sm3_freq0 = <0x5000000>;
			sdc_tm4_sm3_freq1 = <0x405>;
			sdc_tm4_sm4_freq0 = <0x50000>;
			sdc_tm4_sm4_freq1 = <0x408>;
			status = "okay";
			non-removable;
			pinctrl-0 = <0x10b>;
			cd-gpios;
			sunxi-power-save-mode;
			sunxi-dis-signal-vol-sw;
			mmc-ddr-1_8v;
			mmc-hs200-1_8v;
			mmc-hs400-1_8v;
			vmmc = "vcc-emmcv";
			vqmmc = "vcc-emmcvq18";
			vdmmc = "none";
		};

		sdmmc@04020000 {
			compatible = "allwinner,sunxi-mmc-v4p1x";
			device_type = "sdc0";
			reg = <0x00 0x4020000 0x00 0x1000>;
			interrupts = <0x00 0x23 0x104>;
			clocks = <0x07 0x75 0x7b 0x7c 0x7d>;
			clock-names = "osc24m\0pll_periph\0mmc\0ahb\0rst";
			pinctrl-names = "default\0sleep\0uart0";
			pinctrl-1 = <0x7f>;
			pinctrl-2 = <0x80>;
			max-frequency = <0x2faf080>;
			bus-width = <0x04>;
			status = "disabled";
			pinctrl-0 = <0x109>;
			cd-gpios = <0x81 0x05 0x06 0x00 0x01 0x02 0xffffffff>;
			sunxi-power-save-mode;
			sunxi-dis-signal-vol-sw;
			vmmc = "vcc-sdcv";
			vqmmc = "vcc-sdcvq33";
			vdmmc = "vcc-sdcvd";
			ctl-spec-caps = <0x80>;
		};

		sdmmc@04021000 {
			compatible = "allwinner,sunxi-mmc-v4p1x";
			device_type = "sdc1";
			reg = <0x00 0x4021000 0x00 0x1000>;
			interrupts = <0x00 0x24 0x104>;
			clocks = <0x07 0x75 0x82 0x83 0x84>;
			clock-names = "osc24m\0pll_periph\0mmc\0ahb\0rst";
			pinctrl-names = "default\0sleep";
			pinctrl-1 = <0x86>;
			max-frequency = <0x8f0d180>;
			bus-width = <0x04>;
			sunxi-dly-52M-ddr4 = <0x01 0x00 0x00 0x00 0x02>;
			sunxi-dly-104M = <0x01 0x00 0x00 0x00 0x01>;
			sunxi-dly-208M = <0x01 0x00 0x00 0x00 0x01>;
			status = "okay";
			pinctrl-0 = <0x10a>;
			sd-uhs-sdr50;
			sd-uhs-ddr50;
			sd-uhs-sdr104;
			cap-sdio-irq;
			keep-power-in-suspend;
			ignore-pm-notify;
		};

		disp@01000000 {
			compatible = "allwinner,sunxi-disp";
			reg = <0x00 0x1000000 0x00 0x1400000 0x00 0x6510000 0x00 0x100 0x00 0x6511000 0x00 0x800 0x00 0x6515000 0x00 0x800>;
			interrupts = <0x00 0x41 0x104 0x00 0x42 0x104>;
			clocks = <0x87 0x88 0x89 0x8a>;
			boot_disp = <0x00>;
			fb_base = <0x00>;
			iommus = <0x19 0x00 0x00>;
			status = "okay";
			device_type = "disp";
			disp_init_enable = <0x01>;
			disp_mode = <0x00>;
			screen0_output_type = <0x03>;
			screen0_output_mode = <0x0a>;
			screen0_output_format = <0x01>;
			screen0_output_bits = <0x00>;
			screen0_output_eotf = <0x04>;
			screen0_output_cs = <0x101>;
			screen0_output_dvi_hdmi = <0x02>;
			screen0_output_range = <0x02>;
			screen0_output_scan = <0x00>;
			screen0_output_aspect_ratio = <0x08>;
			screen1_output_type = <0x03>;
			screen1_output_mode = <0x02>;
			screen1_output_format = <0x01>;
			screen1_output_bits = <0x00>;
			screen1_output_eotf = <0x04>;
			screen1_output_cs = <0x104>;
			screen1_output_dvi_hdmi = <0x02>;
			screen1_output_range = <0x02>;
			screen1_output_scan = <0x00>;
			screen1_output_aspect_ratio = <0x08>;
			dev0_output_type = <0x04>;
			dev0_output_mode = <0x09>;
			dev0_screen_id = <0x00>;
			dev0_do_hpd = <0x01>;
			dev1_output_type = <0x02>;
			dev1_output_mode = <0x0b>;
			dev1_screen_id = <0x01>;
			dev1_do_hpd = <0x01>;
			dev2_output_type = <0x00>;
			def_output_dev = <0x00>;
			hdmi_mode_check = <0x01>;
			fb0_format = <0x00>;
			fb0_width = <0x780>;
			fb0_height = <0x438>;
			fb1_format = <0x00>;
			fb1_width = <0x00>;
			fb1_height = <0x00>;
			disp_para_zone = <0x01>;
		};

		lcd0@01c0c000 {
			compatible = "allwinner,sunxi-lcd0";
			pinctrl-names = "active\0sleep";
			status = "okay";
			device_type = "lcd0";
			lcd_used = <0x00>;
			lcd_driver_name = "default_lcd";
			lcd_backlight = <0x32>;
			lcd_if = <0x00>;
			lcd_x = <0x320>;
			lcd_y = <0x258>;
			lcd_width = <0x96>;
			lcd_height = <0x5e>;
			lcd_dclk_freq = <0x28>;
			lcd_pwm_used = <0x00>;
			lcd_pwm_ch = <0x00>;
			lcd_pwm_freq = <0xc350>;
			lcd_pwm_pol = <0x01>;
			lcd_pwm_max_limit = <0xff>;
			lcd_hbp = <0xd8>;
			lcd_ht = <0x420>;
			lcd_hspw = <0x80>;
			lcd_vbp = <0x1b>;
			lcd_vt = <0x274>;
			lcd_vspw = <0x04>;
			lcd_lvds_if = <0x00>;
			lcd_lvds_colordepth = <0x01>;
			lcd_lvds_mode = <0x00>;
			lcd_frm = <0x01>;
			lcd_hv_clk_phase = <0x00>;
			lcd_hv_sync_polarity = <0x00>;
			lcd_gamma_en = <0x00>;
			lcd_bright_curve_en = <0x00>;
			lcd_cmap_en = <0x00>;
			lcd_bl_en;
			lcd_bl_en_power = "none";
			lcd_power = "vcc-lcd-0";
			lcd_fix_power = "vcc-dsi-33";
			pinctrl-0 = <0xfc>;
			lcd_pin_power = "vcc-pd";
			pinctrl-1 = <0xfd>;
		};

		lcd1@01c0c001 {
			compatible = "allwinner,sunxi-lcd1";
			pinctrl-names = "active\0sleep";
			status = "okay";
		};

		hdmi@06000000 {
			compatible = "allwinner,sunxi-hdmi";
			reg = <0x00 0x6000000 0x00 0x100000>;
			interrupts = <0x00 0x40 0x00>;
			clocks = <0x8b 0x8c 0x8d 0x8e>;
			pinctrl-names = "ddc_active\0ddc_sleep\0cec_active\0cec_sleep";
			pinctrl-1 = <0x90>;
			pinctrl-2 = <0x91>;
			pinctrl-3 = <0x92>;
			status = "okay";
			device_type = "hdmi";
			hdmi_hdcp_enable = <0x00>;
			hdmi_hdcp22_enable = <0x00>;
			hdmi_cts_compatibility = <0x00>;
			hdmi_cec_support = <0x01>;
			hdmi_cec_super_standby = <0x01>;
			hdmi_skip_bootedid = <0x01>;
			pinctrl-0 = <0xfe>;
			ddc_en_io_ctrl = <0x01>;
			ddc_io_ctrl = <0x81 0x07 0x02 0x01 0xffffffff 0xffffffff 0x00>;
			power_io_ctrl = <0x01>;
			power_en_io = <0xdc 0x0b 0x01 0x01 0xffffffff 0xffffffff 0x01>;
		};

		tv0@01c94000 {
			compatible = "allwinner,sunxi-tv";
			reg = <0x00 0x1e40000 0x00 0x1000>;
			status = "disabled";
			device_type = "tv0";
			dac_src0 = <0x00>;
			dac_type0 = <0x00>;
			interface = <0x01>;
		};

		tr@01000000 {
			compatible = "allwinner,sun50i-tr";
			reg = <0x00 0x1000000 0x00 0x200bc>;
			interrupts = <0x00 0x60 0x104>;
			clocks = <0x87>;
			status = "okay";
		};

		pwm@0300a000 {
			compatible = "allwinner,sunxi-pwm";
			reg = <0x00 0x300a000 0x00 0x3c>;
			clocks = <0x93>;
			pwm-number = <0x02>;
			pwm-base = <0x00>;
			pwms = <0x94 0x95>;
		};

		pwm0@0300a000 {
			compatible = "allwinner,sunxi-pwm0";
			pinctrl-names = "active\0sleep";
			reg_base = <0x300a000>;
			reg_busy_offset = <0x00>;
			reg_busy_shift = <0x1c>;
			reg_enable_offset = <0x00>;
			reg_enable_shift = <0x04>;
			reg_clk_gating_offset = <0x00>;
			reg_clk_gating_shift = <0x06>;
			reg_bypass_offset = <0x00>;
			reg_bypass_shift = <0x09>;
			reg_pulse_start_offset = <0x00>;
			reg_pulse_start_shift = <0x08>;
			reg_mode_offset = <0x00>;
			reg_mode_shift = <0x07>;
			reg_polarity_offset = <0x00>;
			reg_polarity_shift = <0x05>;
			reg_period_offset = <0x04>;
			reg_period_shift = <0x10>;
			reg_period_width = <0x10>;
			reg_active_offset = <0x04>;
			reg_active_shift = <0x00>;
			reg_active_width = <0x10>;
			reg_prescal_offset = <0x00>;
			reg_prescal_shift = <0x00>;
			reg_prescal_width = <0x04>;
			linux,phandle = <0x94>;
			phandle = <0x94>;
			device_type = "pwm0";
			pwm_used = <0x01>;
			pinctrl-0 = <0x101>;
			pinctrl-1 = <0x102>;
		};

		pwm1@0300a000 {
			compatible = "allwinner,sunxi-pwm1";
			pinctrl-names = "active\0sleep";
			reg_base = <0x300a000>;
			reg_busy_offset = <0x00>;
			reg_busy_shift = <0x1d>;
			reg_enable_offset = <0x00>;
			reg_enable_shift = <0x13>;
			reg_clk_gating_offset = <0x00>;
			reg_clk_gating_shift = <0x15>;
			reg_bypass_offset = <0x00>;
			reg_bypass_shift = <0x18>;
			reg_pulse_start_offset = <0x00>;
			reg_pulse_start_shift = <0x17>;
			reg_mode_offset = <0x00>;
			reg_mode_shift = <0x16>;
			reg_polarity_offset = <0x00>;
			reg_polarity_shift = <0x14>;
			reg_period_offset = <0x08>;
			reg_period_shift = <0x10>;
			reg_period_width = <0x10>;
			reg_active_offset = <0x08>;
			reg_active_shift = <0x00>;
			reg_active_width = <0x10>;
			reg_prescal_offset = <0x00>;
			reg_prescal_shift = <0x0f>;
			reg_prescal_width = <0x04>;
			linux,phandle = <0x95>;
			phandle = <0x95>;
			device_type = "pwm1";
			pwm_used = <0x01>;
			pinctrl-0 = <0x103>;
			pinctrl-1 = <0x104>;
		};

		s_pwm@07020c00 {
			compatible = "allwinner,sunxi-s_pwm";
			reg = <0x00 0x7020c00 0x00 0x3c>;
			clocks = <0x96>;
			pwm-number = <0x01>;
			pwm-base = <0x10>;
			pwms = <0x97>;
		};

		spwm0@07020c00 {
			compatible = "allwinner,sunxi-pwm16";
			pinctrl-names = "active\0sleep";
			reg_base = <0x7020c00>;
			reg_busy_offset = <0x00>;
			reg_busy_shift = <0x1c>;
			reg_enable_offset = <0x00>;
			reg_enable_shift = <0x04>;
			reg_clk_gating_offset = <0x00>;
			reg_clk_gating_shift = <0x06>;
			reg_bypass_offset = <0x00>;
			reg_bypass_shift = <0x09>;
			reg_pulse_start_offset = <0x00>;
			reg_pulse_start_shift = <0x08>;
			reg_mode_offset = <0x00>;
			reg_mode_shift = <0x07>;
			reg_polarity_offset = <0x00>;
			reg_polarity_shift = <0x05>;
			reg_period_offset = <0x04>;
			reg_period_shift = <0x10>;
			reg_period_width = <0x10>;
			reg_active_offset = <0x04>;
			reg_active_shift = <0x00>;
			reg_active_width = <0x10>;
			reg_prescal_offset = <0x00>;
			reg_prescal_shift = <0x00>;
			reg_prescal_width = <0x04>;
			linux,phandle = <0x97>;
			phandle = <0x97>;
		};

		boot_disp {
			compatible = "allwinner,boot_disp";
			device_type = "boot_disp";
			auto_hpd = <0x01>;
			output_disp = <0x00>;
			output_type = <0x03>;
			output_mode = <0x0b>;
			hdmi_channel = <0x00>;
			hdmi_mode = <0x04>;
		};

		ac200 {
			compatible = "allwinner,sunxi-ac200";
			clocks = <0x89>;
			pinctrl-names = "active\0sleep\0ccir_clk_active\0ccir_clk_sleep";
			pinctrl-2 = <0x98>;
			pinctrl-3 = <0x99>;
			status = "okay";
			device_type = "ac200";
			tv_used = <0x01>;
			tv_module_name = "tv_ac200";
			tv_twi_used = <0x01>;
			tv_twi_id = <0x03>;
			tv_twi_addr = <0x10>;
			tv_pwm_ch = <0x01>;
			tv_clk_div = <0x05>;
			tv_regulator_name = "vcc-audio-33";
			pinctrl-0 = <0xff>;
			pinctrl-1 = <0x100>;
		};

		vind@0 {
			compatible = "allwinner,sunxi-vin-media\0simple-bus";
			#address-cells = <0x02>;
			#size-cells = <0x02>;
			ranges;
			device_id = <0x00>;
			reg = <0x00 0x6620000 0x00 0x1000>;
			clocks = <0x9a 0x02 0x9b 0x07 0x02>;
			pinctrl-names = "mclk0-default\0mclk0-sleep";
			pinctrl-0 = <0x9c>;
			pinctrl-1 = <0x9d>;
			status = "okay";

			cci@0x0662e000 {
				compatible = "allwinner,sunxi-csi_cci";
				reg = <0x00 0x662e000 0x00 0x1000>;
				interrupts = <0x00 0x48 0x04>;
				clocks = <0x9e>;
				pinctrl-names = "default\0sleep";
				pinctrl-0 = <0x9f>;
				pinctrl-1 = <0xa0>;
				device_id = <0x00>;
				status = "okay";
			};

			csi@0x06621000 {
				device_type = "csi0";
				compatible = "allwinner,sunxi-csi";
				reg = <0x00 0x6621000 0x00 0x1000>;
				interrupts = <0x00 0x46 0x04>;
				pinctrl-names = "default\0sleep";
				pinctrl-1 = <0xa2>;
				device_id = <0x00>;
				iommus = <0x19 0x04 0x01>;
				status = "disabled";
				csi0_sensor_list = <0x00>;
				pinctrl-0 = <0x107 0x108>;

				csi0_dev0 {
					device_type = "csi0_dev0";
					status = "disabled";
					csi0_dev0_mname = "ov5640";
					csi0_dev0_twi_addr = <0x78>;
					csi0_dev0_pos = "rear";
					csi0_dev0_isp_used = <0x01>;
					csi0_dev0_fmt = <0x00>;
					csi0_dev0_stby_mode = <0x00>;
					csi0_dev0_vflip = <0x00>;
					csi0_dev0_hflip = <0x00>;
					csi0_dev0_iovdd = "iovdd-csi";
					csi0_dev0_iovdd_vol = <0x2ab980>;
					csi0_dev0_avdd = "avdd-csi";
					csi0_dev0_avdd_vol = <0x2ab980>;
					csi0_dev0_dvdd = "dvdd-csi-18";
					csi0_dev0_dvdd_vol = <0x16e360>;
					csi0_dev0_afvdd = "afvcc-csi";
					csi0_dev0_afvdd_vol = <0x2ab980>;
					csi0_dev0_power_en;
					csi0_dev0_reset = <0x81 0x04 0x0e 0x01 0x00 0x01 0x00>;
					csi0_dev0_pwdn = <0x81 0x04 0x0f 0x01 0x00 0x01 0x00>;
					csi0_dev0_flash_used = <0x00>;
					csi0_dev0_flash_type = <0x02>;
					csi0_dev0_flash_en;
					csi0_dev0_flash_mode;
					csi0_dev0_flvdd;
					csi0_dev0_flvdd_vol;
					csi0_dev0_af_pwdn;
					csi0_dev0_act_used = <0x00>;
					csi0_dev0_act_name = "ad5820_act";
					csi0_dev0_act_slave = <0x18>;
				};

				csi0_dev1 {
					device_type = "csi0_dev1";
					status = "disabled";
					csi0_dev1_mname;
					csi0_dev1_twi_addr = <0x78>;
					csi0_dev1_pos = "rear";
					csi0_dev1_isp_used = <0x01>;
					csi0_dev1_fmt = <0x00>;
					csi0_dev1_stby_mode = <0x00>;
					csi0_dev1_vflip = <0x00>;
					csi0_dev1_hflip = <0x00>;
					csi0_dev1_iovdd = "iovdd-csi";
					csi0_dev1_iovdd_vol = <0x2ab980>;
					csi0_dev1_avdd = "avdd-csi";
					csi0_dev1_avdd_vol = <0x2ab980>;
					csi0_dev1_dvdd = "dvdd-csi-18";
					csi0_dev1_dvdd_vol = <0x16e360>;
					csi0_dev1_afvdd = "afvcc-csi";
					csi0_dev1_afvdd_vol = <0x2ab980>;
					csi0_dev1_power_en;
					csi0_dev1_reset;
					csi0_dev1_pwdn;
					csi0_dev1_flash_used = <0x00>;
					csi0_dev1_flash_type = <0x02>;
					csi0_dev1_flash_en;
					csi0_dev1_flash_mode;
					csi0_dev1_flvdd;
					csi0_dev1_flvdd_vol;
					csi0_dev1_af_pwdn;
					csi0_dev1_act_used = <0x00>;
					csi0_dev1_act_name = "ad5820_act";
					csi0_dev1_act_slave = <0x18>;
				};
			};

			csi@1 {
				device_type = "csi1";
				compatible = "allwinner,sunxi-csi";
				device_id = <0x01>;
				iommus = <0x19 0x04 0x01>;
				status = "disabled";
			};

			mipi@0 {
				compatible = "allwinner,sunxi-mipi";
				device_id = <0x00>;
				status = "disabled";
			};

			mipi@1 {
				compatible = "allwinner,sunxi-mipi";
				device_id = <0x01>;
				status = "disabled";
			};

			isp@0 {
				compatible = "allwinner,sunxi-isp";
				reg = <0x00 0x2100000 0x00 0x800>;
				interrupts = <0x00 0x56 0x04>;
				device_id = <0x00>;
				iommus = <0x19 0x04 0x01>;
				status = "okay";
				linux,phandle = <0xa5>;
				phandle = <0xa5>;
			};

			isp@1 {
				compatible = "allwinner,sunxi-isp";
				reg = <0x00 0x2100800 0x00 0x800>;
				device_id = <0x01>;
				iommus = <0x19 0x04 0x01>;
				status = "disabled";
				linux,phandle = <0xa6>;
				phandle = <0xa6>;
			};

			scaler@0x02101000 {
				compatible = "allwinner,sunxi-scaler";
				reg = <0x00 0x2101000 0x00 0x400>;
				device_id = <0x00>;
				iommus = <0x19 0x04 0x01>;
				status = "okay";
			};

			scaler@0x02101400 {
				compatible = "allwinner,sunxi-scaler";
				reg = <0x00 0x2101400 0x00 0x400>;
				device_id = <0x01>;
				iommus = <0x19 0x04 0x01>;
				status = "okay";
			};

			scaler@2 {
				compatible = "allwinner,sunxi-scaler";
				device_id = <0x02>;
				iommus = <0x19 0x04 0x01>;
				status = "disabled";
			};

			scaler@3 {
				compatible = "allwinner,sunxi-scaler";
				device_id = <0x03>;
				iommus = <0x19 0x04 0x01>;
				status = "disabled";
			};

			actuator@0 {
				device_type = "actuator0";
				compatible = "allwinner,sunxi-actuator";
				actuator0_name = "ad5820_act";
				actuator0_slave = <0x18>;
				actuator0_af_pwdn;
				actuator0_afvdd = "afvcc-csi";
				actuator0_afvdd_vol = <0x2ab980>;
				status = "disabled";
				linux,phandle = <0xa4>;
				phandle = <0xa4>;
			};

			flash@0 {
				device_type = "flash0";
				compatible = "allwinner,sunxi-flash";
				flash0_type = <0x02>;
				flash0_en;
				flash0_mode;
				flash0_flvdd = [00];
				flash0_flvdd_vol;
				device_id = <0x00>;
				status = "disabled";
				linux,phandle = <0xa3>;
				phandle = <0xa3>;
			};

			sensor@0 {
				device_type = "sensor0";
				sensor0_mname = "ov5640";
				sensor0_twi_cci_id = <0x00>;
				sensor0_twi_addr = <0x78>;
				sensor0_pos = "rear";
				sensor0_isp_used = <0x00>;
				sensor0_fmt = <0x00>;
				sensor0_stby_mode = <0x00>;
				sensor0_vflip = <0x00>;
				sensor0_hflip = <0x00>;
				sensor0_iovdd = "iovdd-csi";
				sensor0_iovdd_vol = <0x2ab980>;
				sensor0_avdd = "avdd-csi";
				sensor0_avdd_vol = <0x2ab980>;
				sensor0_dvdd = "dvdd-csi-18";
				sensor0_dvdd_vol = <0x16e360>;
				sensor0_power_en;
				sensor0_reset = <0x81 0x04 0x0e 0x01 0x00 0x01 0x00>;
				sensor0_pwdn = <0x81 0x04 0x10 0x01 0x00 0x01 0x00>;
				flash_handle = <0xa3>;
				act_handle = <0xa4>;
				status = "okay";
				linux,phandle = <0xa7>;
				phandle = <0xa7>;
			};

			sensor@1 {
				device_type = "sensor1";
				sensor1_mname = "ov5647";
				sensor1_twi_cci_id = <0x00>;
				sensor1_twi_addr = <0x6c>;
				sensor1_pos = "front";
				sensor1_isp_used = <0x00>;
				sensor1_fmt = <0x00>;
				sensor1_stby_mode = <0x00>;
				sensor1_vflip = <0x00>;
				sensor1_hflip = <0x00>;
				sensor1_iovdd = "iovdd-csi";
				sensor1_iovdd_vol = <0x2ab980>;
				sensor1_avdd = "avdd-csi";
				sensor1_avdd_vol = <0x2ab980>;
				sensor1_dvdd = "dvdd-csi-18";
				sensor1_dvdd_vol = <0x16e360>;
				sensor1_power_en;
				sensor1_reset = <0x81 0x04 0x0e 0x01 0x00 0x01 0x00>;
				sensor1_pwdn = <0x81 0x04 0x0f 0x01 0x00 0x01 0x00>;
				flash_handle;
				act_handle;
				status = "okay";
				linux,phandle = <0xa8>;
				phandle = <0xa8>;
			};

			vinc@0x06623000 {
				device_type = "vinc0";
				compatible = "allwinner,sunxi-vin-core";
				reg = <0x00 0x6623000 0x00 0x100>;
				interrupts = <0x00 0x43 0x04>;
				vinc0_csi_sel = <0x00>;
				vinc0_mipi_sel = <0xff>;
				vinc0_isp_sel = <0x00>;
				vinc0_sensor_sel = <0x00>;
				vinc0_sensor_list = <0x00>;
				isp_handle = <0xa5 0xa6>;
				sensor_handle = <0xa7 0xa8>;
				device_id = <0x00>;
				iommus = <0x19 0x04 0x01>;
				status = "okay";
			};

			vinc@0x06623100 {
				device_type = "vinc1";
				compatible = "allwinner,sunxi-vin-core";
				reg = <0x00 0x6623100 0x00 0x100>;
				interrupts = <0x00 0x44 0x04>;
				vinc1_csi_sel = <0x00>;
				vinc1_mipi_sel = <0xff>;
				vinc1_isp_sel = <0x00>;
				vinc1_sensor_sel = <0x01>;
				vinc1_sensor_list = <0x00>;
				isp_handle = <0xa5 0xa6>;
				sensor_handle = <0xa7 0xa8>;
				device_id = <0x01>;
				iommus = <0x19 0x04 0x01>;
				status = "okay";
			};
		};

		vdevice@0 {
			compatible = "allwinner,sun50i-vdevice";
			device_type = "Vdevice";
			pinctrl-names = "default";
			test-gpios = <0x81 0x01 0x00 0x01 0x02 0x02 0x01>;
			status = "disabled";
			pinctrl-0 = <0x10f>;
		};

		emce@01905000 {
			compatible = "allwinner,sunxi-emce";
			device_name = "emce";
			reg = <0x00 0x1905000 0x00 0x100>;
			clock-frequency = <0x11e1a300>;
			clocks = <0xaa 0x1b>;
		};

		ce@1904000 {
			compatible = "allwinner,sunxi-ce";
			device_name = "ce";
			reg = <0x00 0x1904000 0x00 0xa0 0x00 0x1904800 0x00 0xa0>;
			interrupts = <0x00 0x57 0xff01 0x00 0x58 0xff01>;
			clock-frequency = <0x11e1a300>;
			clocks = <0xab 0x1b>;
		};

		deinterlace@0x01420000 {
			#address-cells = <0x01>;
			#size-cells = <0x00>;
			compatible = "allwinner,sunxi-deinterlace";
			reg = <0x00 0x1420000 0x00 0x20c>;
			interrupts = <0x00 0x4f 0x04>;
			clocks = <0xac 0x02>;
			iommus = <0x19 0x02 0x01>;
			status = "okay";
			device_type = "di";
		};

		smartcard@0x05005000 {
			#address-cells = <0x01>;
			#size-cells = <0x00>;
			compatible = "allwinner,sunxi-scr";
			device_type = "scr0";
			reg = <0x00 0x5005000 0x00 0x400>;
			interrupts = <0x00 0x08 0x04>;
			clocks = <0xad 0xae>;
			clock-frequency = <0x16e3600>;
			pinctrl-names = "default\0sleep";
			pinctrl-0 = <0xaf 0xb0>;
			pinctrl-1 = <0xb1>;
			status = "disabled";
		};

		smartcard@0x05005400 {
			#address-cells = <0x01>;
			#size-cells = <0x00>;
			compatible = "allwinner,sunxi-scr";
			device_type = "scr1";
			reg = <0x00 0x5005400 0x00 0x400>;
			interrupts = <0x00 0x09 0x04>;
			clocks = <0xb2 0xae>;
			clock-frequency = <0x16e3600>;
			pinctrl-names = "default\0sleep";
			pinctrl-0 = <0xb3 0xb4>;
			pinctrl-1 = <0xb5>;
			status = "disabled";
		};

		pmu@0 {
			interrupts = <0x00 0x60 0x04>;
			status = "okay";
			device_type = "pmu0";
			compatible = "axpdummy";
			pmu_id = <0x83>;

			powerkey@0 {
				status = "disabled";
				device_type = "powerkey0";
				compatible = "axp806-powerkey";
				pmu_powkey_off_time = <0x1770>;
				pmu_powkey_off_func = <0x00>;
				pmu_powkey_off_en = <0x01>;
				pmu_powkey_long_time = <0x5dc>;
				pmu_powkey_on_time = <0x3e8>;
			};

			regulator@0 {
				status = "okay";
				device_type = "regulator0";
				compatible = "axpdummy-regulator";
				regulator_count = <0x07>;
				regulator1 = "axpdummy_ldo1  none vdd-cpua";
				regulator2 = "axpdummy_ldo2  none vdd-gpu vdd-sys vdd-hdmi vdd-usb vdd-pcie";
				regulator3 = "axpdummy_ldo3  none vcc-dram";
				regulator4 = "axpdummy_ldo4  none vcc-pl vcc-led vcc-ir vcc-io vcc-audio-33 vcc-pg vcc-pm ac-ldoin vcc-wifi1 vcc-wifi2 vcc-wifi-io vcc-tv vcc-emmc-33 vcc-emmcv vcc-emmcvq18 vcc-sdcv vcc-sdcvq33 vcc-sdcvd";
				regulator5 = "axpdummy_ldo5  none vcc-5v";
				regulator6 = "axpdummy_ldo6  none vcc-rtc vdd18-lpddr vcc-usb usb-dvdd vcc-ts vcc-ephy vcc-pcie-slot vdd-dram-18 vdd-bias vcc-emmc-18 vcc-card vcc-pd vcc-uart vcc-camera-33";
				regulator7 = "axpdummy_ldo7   none vdd18-dram vcc18-bias vcc-pll vcc-hdmi vcc-pc vdd-efuse vccio-dcxo";
			};

			axp_gpio@0 {
				gpio-controller;
				#size-cells = <0x00>;
				#gpio-cells = <0x06>;
				status = "okay";
				device_type = "axp_pio";
				linux,phandle = <0xf9>;
				phandle = <0xf9>;
			};

			charger@0 {
				status = "okay";
				device_type = "charger0";
				pmu_bat_unused = <0x01>;
				pmu_pwroff_vol = <0xce4>;
				power_start = <0x00>;
			};
		};

		nmi@0x01f00c00 {
			#address-cells = <0x01>;
			#size-cells = <0x00>;
			compatible = "allwinner,sunxi-nmi";
			reg = <0x00 0x1f00c00 0x00 0x50>;
			nmi_irq_ctrl = <0x0c>;
			nmi_irq_en = <0x40>;
			nmi_irq_status = <0x10>;
			nmi_irq_mask = <0x50>;
			status = "okay";
		};

		nand0@04011000 {
			compatible = "allwinner,sun50iw6-nand";
			device_type = "nand0";
			reg = <0x00 0x4011000 0x00 0x1000>;
			interrupts = <0x00 0x22 0x04>;
			clocks = <0x1b 0xb6 0xb7>;
			pinctrl-names = "default\0sleep";
			pinctrl-1 = <0xba>;
			nand0_regulator1 = "vcc-nand";
			nand0_regulator2 = "none";
			nand0_cache_level = <0x55aaaa55>;
			nand0_flush_cache_num = <0x55aaaa55>;
			nand0_capacity_level = <0x55aaaa55>;
			nand0_id_number_ctl = <0x55aaaa55>;
			nand0_print_level = <0x55aaaa55>;
			nand0_p0 = <0x55aaaa55>;
			nand0_p1 = <0x55aaaa55>;
			nand0_p2 = <0x55aaaa55>;
			nand0_p3 = <0x55aaaa55>;
			status = "okay";
			nand0_support_2ch = <0x00>;
			pinctrl-0 = <0xfa 0xfb>;
		};

		ts0@05060000 {
			compatible = "allwinner,sun50i-tsc";
			device_type = "ts0";
			reg = <0x00 0x5060000 0x00 0x1000>;
			interrupts = <0x00 0x0e 0x04>;
			clocks = <0x02 0xbb>;
			clock-frequency = <0x7270e00>;
			pinctrl-names = "ts0-default\0ts1-default\0ts2-default\0ts3-default\0ts0-sleep\0ts1-sleep\0ts2-sleep\0ts3-sleep";
			pinctrl-0 = <0xbc>;
			pinctrl-1 = <0xbd>;
			pinctrl-2 = <0xbe>;
			pinctrl-3 = <0xbf>;
			pinctrl-4 = <0xc0>;
			pinctrl-5 = <0xc1>;
			pinctrl-6 = <0xc2>;
			pinctrl-7 = <0xc3>;
			ts0config = <0x01>;
			ts1config = <0x00>;
			ts2config = <0x00>;
			ts3config = <0x00>;
			status = "okay";
		};

		thermal_sensor {
			compatible = "allwinner,thermal_sensor";
			reg = <0x00 0x5070400 0x00 0x400>;
			interrupts = <0x00 0x0f 0x00>;
			clocks = <0x07 0xc4>;
			sensor_num = <0x02>;
			combine_num = <0x02>;
			alarm_low_temp = <0x69>;
			alarm_high_temp = <0x6e>;
			alarm_temp_hysteresis = <0x0f>;
			shut_temp = <0x73>;
			status = "okay";

			ths_combine0 {
				compatible = "allwinner,ths_combine0";
				#thermal-sensor-cells = <0x01>;
				combine_sensor_num = <0x01>;
				combine_sensor_type = "cpu";
				combine_sensor_temp_type = "max";
				combine_sensor_id = <0x00>;
				linux,phandle = <0xc5>;
				phandle = <0xc5>;
			};

			ths_combine1 {
				compatible = "allwinner,ths_combine1";
				#thermal-sensor-cells = <0x01>;
				combine_sensor_num = <0x01>;
				combine_sensor_type = "gpu";
				combine_sensor_temp_type = "max";
				combine_sensor_id = <0x01>;
				linux,phandle = <0xcd>;
				phandle = <0xcd>;
			};
		};

		cpu_budget_cool {
			device_type = "cpu_budget_cool";
			compatible = "allwinner,budget_cooling";
			#cooling-cells = <0x02>;
			status = "okay";
			state_cnt = <0x07>;
			cluster_num = <0x01>;
			state0 = <0x1b7740 0x04>;
			state1 = <0x16b480 0x04>;
			state2 = <0x142440 0x03>;
			state3 = <0x107ac0 0x02>;
			state4 = <0xd8cc0 0x01>;
			state5 = <0xafc80 0x01>;
			state6 = <0x75300 0x01>;
			linux,phandle = <0xc7>;
			phandle = <0xc7>;
		};

		gpu_cooling {
			compatible = "allwinner,gpu_cooling";
			reg = <0x00 0x00 0x00 0x00>;
			#cooling-cells = <0x02>;
			status = "okay";
			state_cnt = <0x04>;
			state0 = <0x00>;
			state1 = <0x01>;
			state2 = <0x02>;
			state3 = <0x03>;
			linux,phandle = <0xcf>;
			phandle = <0xcf>;
		};

		thermal-zones {

			cpu_thermal_zone {
				polling-delay-passive = <0x3e8>;
				polling-delay = <0x3e8>;
				thermal-sensors = <0xc5 0x00>;

				trips {

					t0 {
						temperature = <0x3c>;
						type = "passive";
						hysteresis = <0x00>;
						linux,phandle = <0xc6>;
						phandle = <0xc6>;
					};

					t1 {
						temperature = <0x5a>;
						type = "passive";
						hysteresis = <0x00>;
						linux,phandle = <0xc8>;
						phandle = <0xc8>;
					};

					t2 {
						temperature = <0x5f>;
						type = "passive";
						hysteresis = <0x00>;
						linux,phandle = <0xc9>;
						phandle = <0xc9>;
					};

					t3 {
						temperature = <0x64>;
						type = "passive";
						hysteresis = <0x00>;
						linux,phandle = <0xca>;
						phandle = <0xca>;
					};

					t4 {
						temperature = <0x69>;
						type = "passive";
						hysteresis = <0x00>;
						linux,phandle = <0xcb>;
						phandle = <0xcb>;
					};

					t5 {
						temperature = <0x6e>;
						type = "passive";
						hysteresis = <0x00>;
						linux,phandle = <0xcc>;
						phandle = <0xcc>;
					};

					t6 {
						temperature = <0x73>;
						type = "critical";
						hysteresis = <0x00>;
					};
				};

				cooling-maps {

					bind0 {
						contribution = <0x00>;
						trip = <0xc6>;
						cooling-device = <0xc7 0x01 0x01>;
					};

					bind1 {
						contribution = <0x00>;
						trip = <0xc8>;
						cooling-device = <0xc7 0x02 0x02>;
					};

					bind2 {
						contribution = <0x00>;
						trip = <0xc9>;
						cooling-device = <0xc7 0x03 0x03>;
					};

					bind3 {
						contribution = <0x00>;
						trip = <0xca>;
						cooling-device = <0xc7 0x04 0x04>;
					};

					bind4 {
						contribution = <0x00>;
						trip = <0xcb>;
						cooling-device = <0xc7 0x05 0x05>;
					};

					bind5 {
						contribution = <0x00>;
						trip = <0xcc>;
						cooling-device = <0xc7 0x06 0x06>;
					};
				};
			};

			gpu_thermal_zone {
				polling-delay-passive = <0x3e8>;
				polling-delay = <0x7d0>;
				thermal-sensors = <0xcd 0x01>;

				trips {

					t0 {
						temperature = <0x5f>;
						type = "passive";
						hysteresis = <0x00>;
						linux,phandle = <0xce>;
						phandle = <0xce>;
					};

					t1 {
						temperature = <0x64>;
						type = "passive";
						hysteresis = <0x00>;
						linux,phandle = <0xd0>;
						phandle = <0xd0>;
					};

					t2 {
						temperature = <0x69>;
						type = "passive";
						hysteresis = <0x00>;
						linux,phandle = <0xd1>;
						phandle = <0xd1>;
					};

					t3 {
						temperature = <0x73>;
						type = "critical";
						hysteresis = <0x00>;
					};
				};

				cooling-maps {

					bind0 {
						contribution = <0x00>;
						trip = <0xce>;
						cooling-device = <0xcf 0x01 0x01>;
					};

					bind1 {
						contribution = <0x00>;
						trip = <0xd0>;
						cooling-device = <0xcf 0x02 0x02>;
					};

					bind2 {
						contribution = <0x00>;
						trip = <0xd1>;
						cooling-device = <0xcf 0x03 0x03>;
					};
				};
			};
		};

		keyboard {
			compatible = "allwinner,keyboard_1200mv";
			reg = <0x00 0x5070800 0x00 0x400>;
			interrupts = <0x00 0x10 0x00>;
			status = "okay";
			key_cnt = <0x05>;
			key0 = <0x73 0x73>;
			key1 = <0xeb 0x72>;
			key2 = <0x14a 0x8b>;
			key3 = <0x1a4 0x1c>;
			key4 = <0x208 0x66>;
		};

		eth@05020000 {
			compatible = "allwinner,sunxi-gmac";
			reg = <0x00 0x5020000 0x00 0x10000 0x00 0x3000030 0x00 0x04>;
			interrupts = <0x00 0x0c 0x04>;
			interrupt-names = "gmacirq";
			clocks = <0xd2>;
			clock-names = "gmac";
			pinctrl-names = "default";
			phy-mode = "rmii";
			tx-delay = <0x00>;
			rx-delay = <0x00>;
			phy-rst;
			gmac-power0 = "vcc-ephy";
			status = "okay";
			device_type = "gmac0";
			pinctrl-0 = <0xe1>;
			gmac-power1;
			gmac-power2;
		};

		product {
			device_type = "product";
			version = "100";
			machine = "petrel-p1";
		};

		platform {
			device_type = "platform";
			secure_without_OS = <0x00>;
			eraseflag = <0x01>;
			next_work = <0x03>;
		};

		target {
			device_type = "target";
			burn_secure_mode = <0x01>;
			boot_clock = <0x528>;
			storage_type = <0xffffffff>;
			burn_key = <0x00>;
			dragonboard_test = <0x00>;
			power_mode = <0x01>;
			advert_enable = <0x01>;
		};

		secure {
			device_type = "secure";
			dram_region_mbytes = <0x50>;
			drm_region_mbytes = <0x00>;
			drm_region_start_mbytes = <0x00>;
		};

		power_sply {
			device_type = "power_sply";
			dcdca_vol = <0xf4628>;
			aldo2_vol = <0xf4f24>;
			cldo2_vol = <0xce4>;
			cldo3_vol = <0xce4>;
			bldo3_vol = <0x708>;
			bldo4_vol = <0xf4948>;
		};

		gpio_bias {
			device_type = "gpio_bias";
			pc_bias = "axp806:bldo2:1800";
			pg_bias = "axp806:bldo3:1800";
		};

		ir_boot_recovery {
			device_type = "ir_boot_recovery";
			status = "okay";
			ir_work_mode = <0x02>;
			ir_press_times = <0x01>;
			ir_detect_time = <0x3e8>;
			ir_key_no_duplicate = <0x00>;
			ir_recovery_key_code0 = <0xca>;
			ir_addr_code0 = <0xfd01>;
			ir_recovery_key_code1 = <0xd2>;
			ir_addr_code1 = <0xfd01>;
			ir_recovery_key_code2 = <0x99>;
			ir_addr_code2 = <0xfd01>;
			ir_recovery_key_code3 = <0xc1>;
			ir_addr_code3 = <0xfd01>;
		};

		card_boot {
			device_type = "card_boot";
			logical_start = <0xa000>;
			sprite_gpio0 = <0xdc 0x0b 0x04 0x01 0xffffffff 0xffffffff 0x01>;
			next_work = <0x03>;
		};

		key_boot_recovery {
			device_type = "key_boot_recovery";
			status = "okay";
			press_mode_enable = <0x01>;
			key_work_mode = <0x01>;
			short_press_mode = <0x00>;
			long_press_mode = <0x02>;
			key_press_time = <0x7d0>;
			recovery_key = <0xdc 0x0b 0x02 0x00 0xffffffff 0xffffffff 0xffffffff>;
		};

		boot_init_gpio {
			device_type = "boot_init_gpio";
			status = "okay";
			gpio0 = <0xdc 0x0b 0x04 0x01 0xffffffff 0xffffffff 0x01>;
		};

		pm_para {
			device_type = "pm_para";
			standby_mode = <0x01>;
			disable_alarm_wakeup = <0x01>;
		};

		card0_boot_para {
			device_type = "card0_boot_para";
			card_ctrl = <0x00>;
			card_high_speed = <0x01>;
			card_line = <0x04>;
			pinctrl-0 = <0xdd>;
		};

		card2_boot_para {
			device_type = "card2_boot_para";
			card_ctrl = <0x02>;
			card_high_speed = <0x01>;
			card_line = <0x08>;
			pinctrl-0 = <0xde>;
			sdc_ex_dly_used = <0x02>;
			sdc_io_1v8 = <0x01>;
			sdc_tm4_hs400_max_freq = <0x64>;
			sdc_tm4_hs200_max_freq = <0x96>;
		};

		twi_para {
			device_type = "twi_para";
			twi_port = <0x00>;
			twi_scl;
			twi_sda;
		};

		uart_para {
			device_type = "uart_para";
			uart_debug_port = <0x00>;
			pinctrl-0 = <0xdf>;
		};

		jtag_para {
			device_type = "jtag_para";
			jtag_enable = <0x00>;
			pinctrl-0 = <0xe0>;
		};

		clock {
			device_type = "clock";
			pll4 = <0x12c>;
			pll6 = <0x258>;
			pll8 = <0x168>;
			pll9 = <0x129>;
			pll10 = <0x108>;
		};

		rtp_para {
			device_type = "rtp_para";
			rtp_used = <0x00>;
			rtp_screen_size = <0x05>;
			rtp_regidity_level = <0x05>;
			rtp_press_threshold_enable = <0x00>;
			rtp_press_threshold = <0x1f40>;
			rtp_sensitive_level = <0x0f>;
			rtp_exchange_x_y_flag = <0x00>;
		};

		ctp {
			device_type = "ctp";
			compatible = "allwinner,sun50i-ctp-para";
			status = "disabled";
			ctp_twi_id = <0x00>;
			ctp_twi_addr = <0x5d>;
			ctp_screen_max_x = <0x500>;
			ctp_screen_max_y = <0x320>;
			ctp_revert_x_flag = <0x01>;
			ctp_revert_y_flag = <0x01>;
			ctp_exchange_x_y_flag = <0x01>;
			ctp_int_port = <0x81 0x07 0x04 0x06 0xffffffff 0xffffffff 0xffffffff>;
			ctp_wakeup = <0x81 0x07 0x08 0x01 0xffffffff 0xffffffff 0x01>;
			ctp_power_ldo = "vcc-ctp";
			ctp_power_ldo_vol = <0xce4>;
			ctp_power_io;
		};

		ctp_list {
			device_type = "ctp_list";
			compatible = "allwinner,sun50i-ctp-list";
			ctp_det_used = <0x00>;
			ft5x_ts = <0x01>;
			gt82x = <0x01>;
			gslX680 = <0x01>;
			gt9xx_ts = <0x00>;
			gt9xxnew_ts = <0x01>;
			gt811 = <0x01>;
			zet622x = <0x01>;
			aw5306_ts = <0x01>;
		};

		tkey_para {
			device_type = "tkey_para";
			tkey_used = <0x00>;
			tkey_twi_id;
			tkey_twi_addr;
			tkey_int;
		};

		motor_para {
			device_type = "motor_para";
			motor_used = <0x01>;
			motor_shake = <0xf9 0xfffe 0x03 0x01 0xffffffff 0xffffffff 0x01>;
		};

		esm {
			device_type = "esm";
			esm_img_size_addr = <0x00>;
			esm_img_buff_addr = <0x00>;
		};

		pwm16 {
			device_type = "pwm16";
			status = "disabled";
			pinctrl-0 = <0x105>;
			pinctrl-1 = <0x106>;
		};

		tvout_para {
			device_type = "tvout_para";
			tvout_used;
			tvout_channel_num;
			tv_en;
		};

		tvin_para {
			device_type = "tvin_para";
			tvin_used;
			tvin_channel_num;
		};

		smc {
			device_type = "smc";
			smc_used;
			smc_rst;
			smc_vppen;
			smc_vppp;
			smc_det;
			smc_vccen;
			smc_sck;
			smc_sda;
		};

		gpio_para {
			device_type = "gpio_para";
			compatible = "allwinner,sunxi-init-gpio";
			status = "okay";
			gpio_num = <0x03>;
			gpio_pin_1 = <0xdc 0x0b 0x04 0x01 0xffffffff 0xffffffff 0x01>;
			gpio_pin_2 = <0xdc 0x0b 0x03 0x01 0xffffffff 0xffffffff 0x00>;
			gpio_pin_3 = <0xdc 0x0b 0x07 0x01 0xffffffff 0xffffffff 0x00>;
			normal_led = "gpio_pin_1";
			standby_led = "gpio_pin_2";
			network_led = "gpio_pin_3";
			easy_light_used = <0x01>;
			normal_led_light = <0x01>;
			standby_led_light = <0x01>;
			network_led_light = <0x01>;
		};

		usbc3 {
			device_type = "usbc3";
			status = "disabled";
			usb_drv_vbus_gpio;
			usb_host_init_state = <0x01>;
			usb_regulator_io = "nocare";
			usb_wakeup_suspend = <0x00>;
		};

		serial_feature {
			device_type = "serial_feature";
			sn_filename = "sn.txt";
		};

		gsensor {
			device_type = "gsensor";
			compatible = "allwinner,sun50i-gsensor-para";
			status = "disabled";
			gsensor_twi_id = <0x01>;
			gsensor_twi_addr = <0x18>;
			gsensor_int1 = <0x81 0x00 0x09 0x06 0x01 0xffffffff 0xffffffff>;
			gsensor_int2;
			gsensor_vcc_io = "vcc-deviceio";
			gsensor_vcc_io_val = <0xc1c>;
		};

		gsensor_list_para {
			device_type = "gsensor_list_para";
			compatible = "allwinner,sun50i-gsensor-list-para";
			gsensor_det_used = <0x00>;
			lsm9ds0_acc_mag = <0x01>;
			bma250 = <0x01>;
			mma8452 = <0x01>;
			mma7660 = <0x01>;
			mma865x = <0x01>;
			afa750 = <0x01>;
			lis3de_acc = <0x01>;
			lis3dh_acc = <0x01>;
			kxtik = <0x01>;
			dmard10 = <0x00>;
			dmard06 = <0x01>;
			mxc622x = <0x01>;
			fxos8700 = <0x01>;
			lsm303d = <0x00>;
		};

		3g_para {
			device_type = "3g_para";
			status = "disabled";
			3g_usbc_num = <0x02>;
			3g_uart_num = <0x00>;
			bb_vbat = <0xdc 0x0b 0x03 0x01 0xffffffff 0xffffffff 0x00>;
			bb_host_wake = <0xdc 0x0c 0x00 0x01 0xffffffff 0xffffffff 0x00>;
			bb_on = <0xdc 0x0c 0x01 0x01 0xffffffff 0xffffffff 0x00>;
			bb_pwr_on = <0xdc 0x0c 0x03 0x01 0xffffffff 0xffffffff 0x00>;
			bb_wake = <0xdc 0x0c 0x04 0x01 0xffffffff 0xffffffff 0x00>;
			bb_rf_dis = <0xdc 0x0c 0x05 0x01 0xffffffff 0xffffffff 0x00>;
			bb_rst = <0xdc 0x0c 0x06 0x01 0xffffffff 0xffffffff 0x00>;
			3g_int;
		};

		gy_para {
			device_type = "gy_para";
			compatible = "allwinner,sun50i-gyr_sensors-para";
			gy_used = <0x00>;
			gy_twi_id = <0x02>;
			gy_twi_addr = <0x6a>;
			gy_int1 = <0x81 0x00 0x0a 0x06 0x01 0xffffffff 0xffffffff>;
			gy_int2;
		};

		gy_list_para {
			device_type = "gy_list_para";
			compatible = "allwinner,sun50i-gyr_sensors-list-para";
			gy_det_used = <0x01>;
			lsm9ds0_gyr = <0x01>;
			l3gd20_gyr = <0x00>;
			bmg160_gyr = <0x01>;
		};

		ls_para {
			device_type = "ls_para";
			compatible = "allwinner,sun50i-lsensors-para";
			ls_used = <0x00>;
			ls_twi_id = <0x02>;
			ls_twi_addr = <0x23>;
			ls_int = <0x81 0x00 0x0c 0x06 0x01 0xffffffff 0xffffffff>;
		};

		ls_list_para {
			device_type = "ls_list_para";
			compatible = "allwinner,sun50i-lsensors-list-para";
			ls_det_used = <0x01>;
			ltr_501als = <0x01>;
			jsa1212 = <0x00>;
			jsa1127 = <0x01>;
		};

		compass_para {
			device_type = "compass_para";
			compatible = "allwinner,sun50i-compass-para";
			compass_used = <0x00>;
			compass_twi_id = <0x02>;
			compass_twi_addr = <0x0d>;
			compass_int = <0x81 0x00 0x0b 0x06 0x01 0xffffffff 0xffffffff>;
		};

		compass_list_para {
			device_type = "compass_list_para";
			compatible = "allwinner,sun50i-compass-list-para";
			compass_det_used = <0x01>;
			lsm9ds0 = <0x01>;
			lsm303d = <0x00>;
			akm8963 = <0x01>;
		};

		box_standby_led {
			device_type = "box_standby_led";
			gpio0 = <0xdc 0x0b 0x04 0x01 0xffffffff 0xffffffff 0x00>;
		};

		gpio_power_key {
			device_type = "gpio_power_key";
			compatible = "allwinner,sunxi-gpio-power-key";
			status = "disabled";
			key_io = <0xdc 0x0b 0x05 0x00 0xffffffff 0xffffffff 0x00>;
			trigger_mode = <0x01>;
		};

		auto_print {
			device_type = "auto_print";
			status = "disabled";
		};

		gpio_keys {
			device_type = "gpio_keys";
			status = "okay";
			compatible = "gpio-keys";

			button {
				device_type = "button";
				label = "RecoveryKey";
				linux,code = <0x2f5>;
				linux,input-type = <0x01>;
				gpios = <0xdc 0x0b 0x02 0x01 0xffffffff 0xffffffff 0x01>;
			};
		};

		empty {
			device_type = "empty";
		};
	};

	aliases {
		serial0 = "/soc@03000000/uart@05000000\0/soc@03000000/uart@05000000";
		serial1 = "/soc@03000000/uart@05000400\0/soc@03000000/uart@05000400";
		serial2 = "/soc@03000000/uart@05000800\0/soc@03000000/uart@05000800";
		serial3 = "/soc@03000000/uart@05000c00\0/soc@03000000/uart@05000c00";
		twi0 = "/soc@03000000/twi@0x05002000\0/soc@03000000/twi@0x05002000";
		twi1 = "/soc@03000000/twi@0x05002400\0/soc@03000000/twi@0x05002400";
		twi2 = "/soc@03000000/twi@0x05002800\0/soc@03000000/twi@0x05002800";
		twi3 = "/soc@03000000/twi@0x05002c00\0/soc@03000000/twi@0x05002c00";
		spi0 = "/soc@03000000/spi@05010000\0/soc@03000000/spi@05010000";
		spi1 = "/soc@03000000/spi@05011000\0/soc@03000000/spi@05011000";
		pcie = "/soc@03000000/pcie@0x05400000\0/soc@03000000/pcie@0x05400000";
		scr0 = "/soc@03000000/smartcard@0x05005000\0/soc@03000000/smartcard@0x05005000";
		scr1 = "/soc@03000000/smartcard@0x05005400\0/soc@03000000/smartcard@0x05005400";
		gmac0 = "/soc@03000000/eth@05020000\0/soc@03000000/eth@05020000";
		global_timer0 = "/soc@03000000/timer@03009000\0/soc@03000000/timer@03009000";
		mmc0 = "/soc@03000000/sdmmc@04020000\0/soc@03000000/sdmmc@04020000";
		mmc2 = "/soc@03000000/sdmmc@04022000\0/soc@03000000/sdmmc@04022000";
		nand0 = "/soc@03000000/nand0@04011000\0/soc@03000000/nand0@04011000";
		disp = "/soc@03000000/disp@01000000\0/soc@03000000/disp@01000000";
		lcd0 = "/soc@03000000/lcd0@01c0c000\0/soc@03000000/lcd0@01c0c000";
		lcd1 = "/soc@03000000/lcd1@01c0c001\0/soc@03000000/lcd1@01c0c001";
		hdmi = "/soc@03000000/hdmi@06000000\0/soc@03000000/hdmi@06000000";
		pwm = "/soc@03000000/pwm@0300a000\0/soc@03000000/pwm@0300a000";
		pwm0 = "/soc@03000000/pwm0@0300a000\0/soc@03000000/pwm0@0300a000";
		pwm1 = "/soc@03000000/pwm1@0300a000\0/soc@03000000/pwm1@0300a000";
		tv0 = "/soc@03000000/tv0@01c94000\0/soc@03000000/tv0@01c94000";
		s_pwm = "/soc@03000000/s_pwm@07020c00\0/soc@03000000/s_pwm@07020c00";
		spwm0 = "/soc@03000000/spwm0@07020c00\0/soc@03000000/spwm0@07020c00";
		boot_disp = "/soc@03000000/boot_disp\0/soc@03000000/boot_disp";
		charger0 = "/soc@03000000/pmu@0/charger@0\0/soc@03000000/pmu@0/charger@0";
		regulator0 = "/soc@03000000/pmu@0/regulator@0\0/soc@03000000/pmu@0/regulator@0";
	};

	chosen {
		bootargs = "earlyprintk=sunxi-uart,0x05000000 loglevel=8 initcall_debug=1 console=ttyS0 init=/init";
		linux,initrd-start = <0x00 0x00>;
		linux,initrd-end = <0x00 0x00>;
	};

	cpus {
		#address-cells = <0x02>;
		#size-cells = <0x00>;

		cpu@0 {
			device_type = "cpu";
			compatible = "arm,cortex-a53\0arm,armv8";
			reg = <0x00 0x00>;
			enable-method = "psci";
			cpufreq_tbl = <0x75300 0x9e340 0xc7380 0xd8cc0 0x107ac0 0x142440 0x16b480 0x1b7740>;
			clock-latency = <0x1e8480>;
			clock-frequency = <0x4ead9a00>;
			cpu-idle-states = <0xd4 0xd5 0xd6>;
		};

		cpu@1 {
			device_type = "cpu";
			compatible = "arm,cortex-a53\0arm,armv8";
			reg = <0x00 0x01>;
			enable-method = "psci";
			clock-frequency = <0x4ead9a00>;
			cpu-idle-states = <0xd4 0xd5 0xd6>;
		};

		cpu@2 {
			device_type = "cpu";
			compatible = "arm,cortex-a53\0arm,armv8";
			reg = <0x00 0x02>;
			enable-method = "psci";
			clock-frequency = <0x4ead9a00>;
			cpu-idle-states = <0xd4 0xd5 0xd6>;
		};

		cpu@3 {
			device_type = "cpu";
			compatible = "arm,cortex-a53\0arm,armv8";
			reg = <0x00 0x03>;
			enable-method = "psci";
			clock-frequency = <0x4ead9a00>;
			cpu-idle-states = <0xd4 0xd5 0xd6>;
		};

		idle-states {
			entry-method = "arm,psci";

			cpu-sleep-0 {
				compatible = "arm,idle-state";
				arm,psci-suspend-param = <0x10000>;
				entry-latency-us = <0xfa0>;
				exit-latency-us = <0x2710>;
				min-residency-us = <0x3a98>;
				linux,phandle = <0xd4>;
				phandle = <0xd4>;
			};

			cluster-sleep-0 {
				compatible = "arm,idle-state";
				arm,psci-suspend-param = <0x1010000>;
				entry-latency-us = <0xc350>;
				exit-latency-us = <0x186a0>;
				min-residency-us = <0x3d090>;
				linux,phandle = <0xd5>;
				phandle = <0xd5>;
			};

			sys-sleep-0 {
				compatible = "arm,idle-state";
				arm,psci-suspend-param = <0x2010000>;
				entry-latency-us = <0x186a0>;
				exit-latency-us = <0x1e8480>;
				min-residency-us = <0x44aa20>;
				linux,phandle = <0xd6>;
				phandle = <0xd6>;
			};
		};
	};

	psci {
		compatible = "arm,psci-0.2";
		method = "smc";
		psci_version = <0x84000000>;
		cpu_suspend = <0xc4000001>;
		cpu_off = <0x84000002>;
		cpu_on = <0xc4000003>;
		affinity_info = <0xc4000004>;
		migrate = <0xc4000005>;
		migrate_info_type = <0x84000006>;
		migrate_info_up_cpu = <0xc4000007>;
		system_off = <0x84000008>;
		system_reset = <0x84000009>;
	};

	n_brom {
		compatible = "allwinner,n-brom";
		reg = <0x00 0x00 0x00 0xa000>;
	};

	s_brom {
		compatible = "allwinner,s-brom";
		reg = <0x00 0x00 0x00 0x10000>;
	};

	sram_ctrl {
		device_type = "sram_ctrl";
		compatible = "allwinner,sram_ctrl";
		reg = <0x00 0x3000000 0x00 0x100>;
	};

	sram_a1 {
		compatible = "allwinner,sram_a1";
		reg = <0x00 0x20000 0x00 0x8000>;
	};

	sram_a2 {
		compatible = "allwinner,sram_a2";
		reg = <0x00 0x100000 0x00 0x14000>;
	};

	prcm {
		compatible = "allwinner,prcm";
		reg = <0x00 0x1f01400 0x00 0x400>;
	};

	cpuscfg {
		compatible = "allwinner,cpuscfg";
		reg = <0x00 0x1f01c00 0x00 0x400>;
	};

	ion {
		compatible = "allwinner,sunxi-ion";

		system {
			type = <0x00>;
		};

		system_contig {
			type = <0x01>;
		};

		cma {
			type = <0x04>;
		};

		secure {
			type = <0x06>;
		};
	};

	dram {
		compatible = "allwinner,dram";
		clocks = <0xd7>;
		clock-names = "pll_ddr";
		dram_clk = <0x00>;
		dram_type = <0x07>;
		dram_zq = <0x3b3bfb>;
		dram_odt_en = <0x31>;
		dram_para1 = <0x30fa>;
		dram_para2 = <0x4000000>;
		dram_mr0 = <0x1c70>;
		dram_mr1 = <0x40>;
		dram_mr2 = <0x18>;
		dram_mr3 = <0x01>;
		dram_tpr0 = <0x48a192>;
		dram_tpr1 = <0x1b1a94b>;
		dram_tpr2 = <0x61043>;
		dram_tpr3 = <0x78787896>;
		dram_tpr4 = <0x00>;
		dram_tpr5 = <0x00>;
		dram_tpr6 = "\t\t\t";
		dram_tpr7 = <0x4d462a3e>;
		dram_tpr8 = <0x00>;
		dram_tpr9 = <0x00>;
		dram_tpr10 = <0x00>;
		dram_tpr11 = <0x440000>;
		dram_tpr12 = <0x00>;
		dram_tpr13 = <0x8000>;
		device_type = "dram";
		dram_mr4 = <0x00>;
		dram_mr5 = <0x400>;
		dram_mr6 = <0x848>;
	};

	memory@40000000 {
		device_type = "memory";
		reg = <0x00 0x40000000 0x00 0x20000000>;
	};

	interrupt-controller@03020000 {
		compatible = "arm,cortex-a15-gic\0arm,cortex-a9-gic";
		#interrupt-cells = <0x03>;
		#address-cells = <0x00>;
		device_type = "gic";
		interrupt-controller;
		reg = <0x00 0x3021000 0x00 0x1000 0x00 0x3022000 0x00 0x2000 0x00 0x3024000 0x00 0x2000 0x00 0x3026000 0x00 0x2000>;
		interrupts = <0x01 0x09 0xf04>;
		linux,phandle = <0x01>;
		phandle = <0x01>;
	};

	sunxi-sid@03006000 {
		compatible = "allwinner,sunxi-sid";
		device_type = "sid";
		reg = <0x00 0x3006000 0x00 0x1000>;
	};

	sunxi-chipid@03006200 {
		compatible = "allwinner,sunxi-chipid";
		device_type = "chipid";
		reg = <0x00 0x3006200 0x00 0x200>;
	};

	timer {
		compatible = "arm,armv8-timer";
		interrupts = <0x01 0x0d 0xff01 0x01 0x0e 0xff01 0x01 0x0b 0xff01 0x01 0x0a 0xff01>;
		clock-frequency = <0x16e3600>;
	};

	pmu {
		compatible = "arm,armv8-pmuv3";
		interrupts = <0x00 0x8c 0x04 0x00 0x8d 0x04 0x00 0x8e 0x04 0x00 0x8f 0x04>;
	};

	dvfs_table {
		compatible = "allwinner,dvfs_table";
		multi-vf-table;

		dvfs_table_0 {
			max_freq = <0x58b11400>;
			min_freq = <0x1c9c3800>;
			lv_count = <0x08>;
			lv1_freq = <0x6b49d200>;
			lv1_volt = <0x488>;
			lv1_pval = <0x514>;
			lv2_freq = <0x58b11400>;
			lv2_volt = <0x424>;
			lv2_pval = <0x514>;
			lv3_freq = <0x4ead9a00>;
			lv3_volt = <0x3e8>;
			lv3_pval = <0x514>;
			lv4_freq = "@_~";
			lv4_volt = <0x3ac>;
			lv4_pval = <0x514>;
			lv5_freq = <0x34edce00>;
			lv5_volt = <0x370>;
			lv5_pval = <0x514>;
			lv6_freq = <0x00>;
			lv6_volt = <0x370>;
			lv6_pval = <0x514>;
			lv7_freq = <0x00>;
			lv7_volt = <0x370>;
			lv7_pval = <0x514>;
			lv8_freq = <0x00>;
			lv8_volt = <0x370>;
			lv8_pval = <0x514>;
			device_type = "dvfs_table_0";
		};

		dvfs_table_1 {
			max_freq = <0x58b11400>;
			min_freq = <0x1c9c3800>;
			lv_count = <0x08>;
			lv1_freq = <0x6b49d200>;
			lv1_volt = <0x44c>;
			lv1_pval = <0x514>;
			lv2_freq = <0x58b11400>;
			lv2_volt = <0x3e8>;
			lv2_pval = <0x514>;
			lv3_freq = <0x4ead9a00>;
			lv3_volt = <0x3ac>;
			lv3_pval = <0x514>;
			lv4_freq = "@_~";
			lv4_volt = <0x370>;
			lv4_pval = <0x514>;
			lv5_freq = <0x34edce00>;
			lv5_volt = <0x334>;
			lv5_pval = <0x514>;
			lv6_freq = <0x00>;
			lv6_volt = <0x334>;
			lv6_pval = <0x514>;
			lv7_freq = <0x00>;
			lv7_volt = <0x334>;
			lv7_pval = <0x514>;
			lv8_freq = <0x00>;
			lv8_volt = <0x334>;
			lv8_pval = <0x514>;
			device_type = "dvfs_table_1";
		};

		dvfs_table_2 {
			max_freq = <0x58b11400>;
			min_freq = <0x1c9c3800>;
			lv_count = <0x08>;
			lv1_freq = <0x6b49d200>;
			lv1_volt = <0x424>;
			lv1_pval = <0x514>;
			lv2_freq = <0x58b11400>;
			lv2_volt = <0x3c0>;
			lv2_pval = <0x514>;
			lv3_freq = <0x4ead9a00>;
			lv3_volt = <0x384>;
			lv3_pval = <0x514>;
			lv4_freq = "@_~";
			lv4_volt = <0x348>;
			lv4_pval = <0x514>;
			lv5_freq = <0x34edce00>;
			lv5_volt = <0x320>;
			lv5_pval = <0x514>;
			lv6_freq = <0x00>;
			lv6_volt = <0x320>;
			lv6_pval = <0x514>;
			lv7_freq = <0x00>;
			lv7_volt = <0x320>;
			lv7_pval = <0x514>;
			lv8_freq = <0x00>;
			lv8_volt = <0x320>;
			lv8_pval = <0x514>;
			device_type = "dvfs_table_2";
		};
	};

	dramfreq {
		compatible = "allwinner,sunxi-dramfreq";
		reg = <0x00 0x4002000 0x00 0x1000 0x00 0x4003000 0x00 0x3000 0x00 0x3001000 0x00 0x1000>;
		interrupts = <0x00 0x21 0x04>;
		clocks = <0xd7>;
		status = "okay";
	};

	uboot {
	};

	iommu@030f0000 {
		compatible = "allwinner,sunxi-iommu";
		reg = <0x00 0x30f0000 0x00 0x1000>;
		interrupts = <0x00 0x39 0x04>;
		interrupt-names = "iommu-irq";
		clocks = <0xd8>;
		clock-names = "iommu";
		#iommu-cells = <0x02>;
		status = "okay";
		linux,phandle = <0x19>;
		phandle = <0x19>;
	};

	gpu@0x01800000 {
		device_type = "gpu";
		compatible = "arm,mali-t720\0arm,mali-midgard";
		reg = <0x00 0x1800000 0x00 0x4000>;
		interrupts = <0x00 0x53 0x04 0x00 0x54 0x04 0x00 0x55 0x04>;
		interrupt-names = "GPU\0JOB\0MMU";
		clocks = <0xd9 0xda>;
		clock-names = "clk_parent\0clk_mali";
		operating-points = <0xb8920 0xfde80 0x98580 0xe7ef0 0x8ca00 0xe30d0 0x83d60 0xde2b0 0x7b0c0 0xd9490 0x6f540 0xd4670 0x69780 0xd1f60 0x668a0 0xcf850 0x639c0 0xcd140 0x5dc00 0xcaa30 0x57e40 0xc8320 0x52080 0xc5c10 0x4c2c0 0xc5c10 0x40740 0xc5c10 0x34bc0 0xc5c10>;
		independent_power = <0x00>;
		gpu_idle = <0x00>;
		dvfs_status = <0x01>;
		temp_ctrl_status = <0x01>;
		scene_ctrl_status = <0x01>;
		max_normal_level = <0x0d>;
	};

	wlan {
		compatible = "allwinner,sunxi-wlan";
		wlan_busnum = <0x01>;
		wlan_usbnum = <0x03>;
		wlan_power;
		wlan_io_regulator = "vcc-wifi-io";
		status = "okay";
		device_type = "wlan";
		wlan_power1 = "vcc-wifi1";
		wlan_power2 = "vcc-wifi2";
		wlan_en;
		wlan_regon = <0xdc 0x0c 0x03 0x01 0xffffffff 0xffffffff 0x00>;
		wlan_hostwake = <0xdc 0x0c 0x00 0x00 0xffffffff 0xffffffff 0x00>;
	};

	bt {
		compatible = "allwinner,sunxi-bt";
		clocks = <0xdb>;
		bt_power = "vcc-wifi";
		bt_io_regulator = "vcc-wifi-io";
		status = "okay";
		device_type = "bt";
		bt_rst_n = <0xdc 0x0c 0x04 0x01 0xffffffff 0xffffffff 0x00>;
	};

	btlpm {
		compatible = "allwinner,sunxi-btlpm";
		uart_index = <0x01>;
		status = "okay";
		device_type = "btlpm";
		bt_hostwake_enable = <0x01>;
		bt_wake;
		bt_hostwake = <0xdc 0x0c 0x01 0x06 0xffffffff 0xffffffff 0x00>;
	};
};
